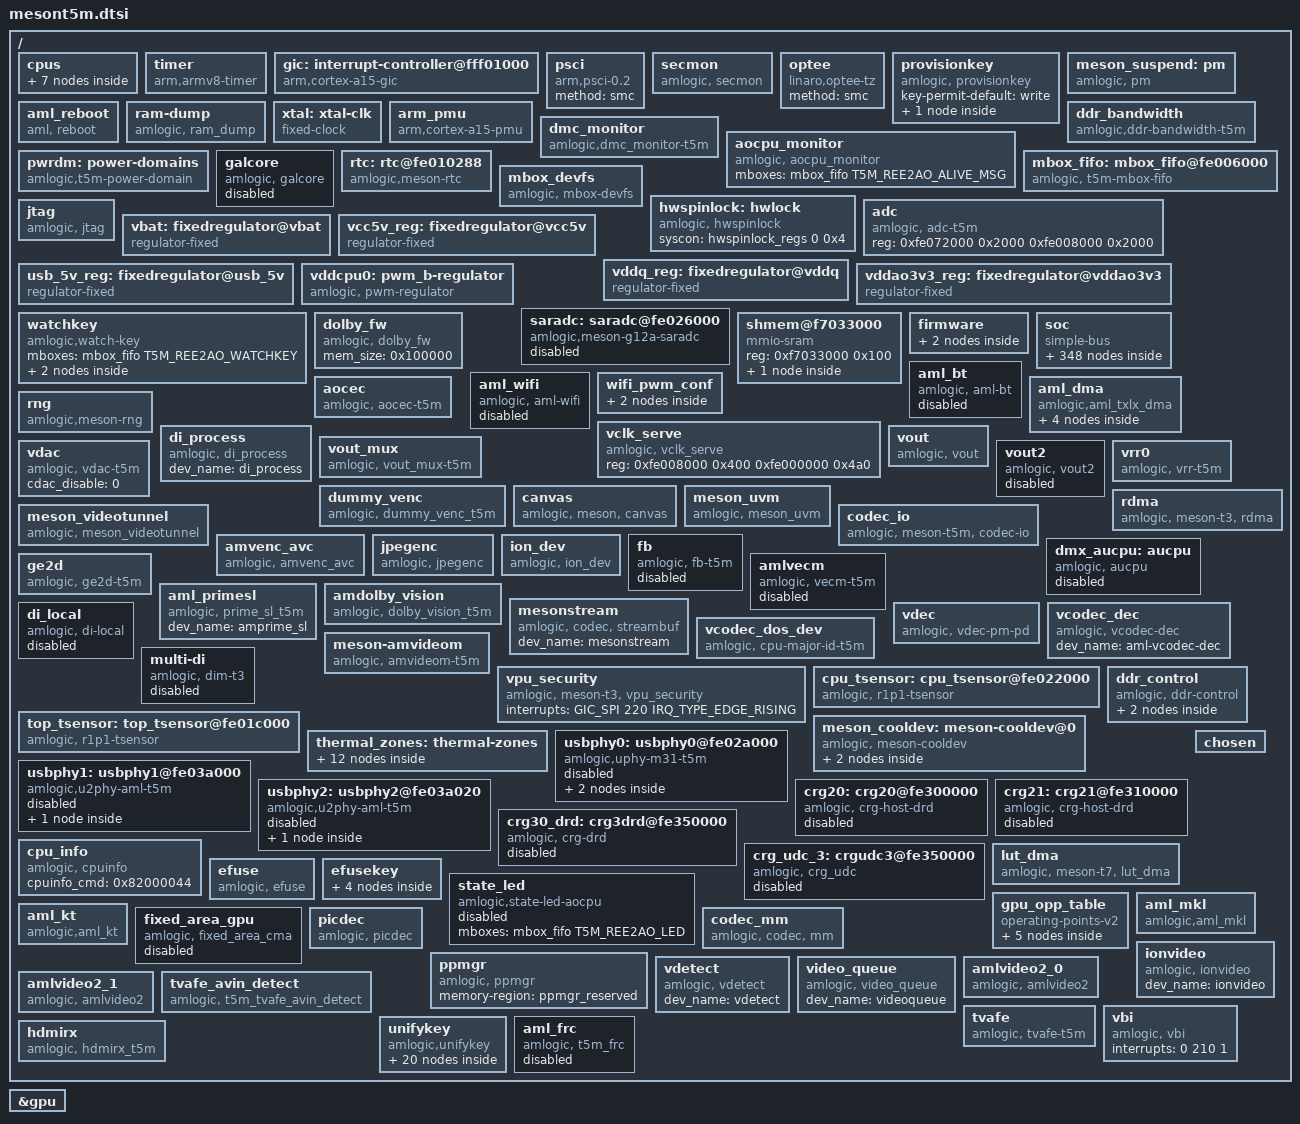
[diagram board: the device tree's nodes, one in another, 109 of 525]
// SPDX-License-Identifier: (GPL-2.0+ OR MIT)
/*
 * Copyright (c) 2019 Amlogic, Inc. All rights reserved.
 */

#include <dt-bindings/interrupt-controller/irq.h>
#include <dt-bindings/interrupt-controller/arm-gic.h>
#include <dt-bindings/reset/amlogic,meson-t5m-reset.h>
#include <dt-bindings/clock/t5m-clkc.h>
#include <dt-bindings/clock/amlogic,t5m-scmi-clk.h>
#include <dt-bindings/clock/amlogic,t3-audio-clk.h>
#include <dt-bindings/gpio/gpio.h>
#include <dt-bindings/gpio/meson-t5m-gpio.h>
#include <dt-bindings/power/t5m-pd.h>
#include <dt-bindings/pwm/pwm.h>
#include <dt-bindings/pwm/meson.h>
#include <dt-bindings/input/input.h>
#include <dt-bindings/input/meson_ir.h>
#include <dt-bindings/iio/adc/amlogic-saradc.h>
#include "meson-ir-map.dtsi"
#include "meson-valhall.dtsi"
#include <dt-bindings/mailbox/t5m-mbox.h>
#include <dt-bindings/thermal/thermal.h>
#include <dt-bindings/thermal/ddr-params.h>
#include <dt-bindings/hwspinlock/amlogic,hwspinlock.h>
#include <dt-bindings/leds/leds-meson.h>

/ {
	cpus:cpus {
		#address-cells = <1>;
		#size-cells = <0>;

		CPU0:cpu@0 {
			device_type = "cpu";
			compatible = "arm,cortex-a55","arm,armv8";
			reg = <0x0>;
			enable-method = "psci";
			cpu-idle-states = <&CPU_SLEEP_0 &SYSTEM_SLEEP_0>;
			#cooling-cells = <2>;
			dynamic-power-coefficient = <230>;
		};

		CPU1:cpu@1{
			device_type = "cpu";
			compatible = "arm,cortex-a55","arm,armv8";
			reg = <0x100>;
			enable-method = "psci";
			cpu-idle-states = <&CPU_SLEEP_0 &SYSTEM_SLEEP_0>;
			#cooling-cells = <2>;
			dynamic-power-coefficient = <230>;
		};

		CPU2:cpu@2 {
			device_type = "cpu";
			compatible = "arm,cortex-a55","arm,armv8";
			reg = <0x200>;
			enable-method = "psci";
			cpu-idle-states = <&CPU_SLEEP_0 &SYSTEM_SLEEP_0>;
			#cooling-cells = <2>;
			dynamic-power-coefficient = <230>;
		};

		CPU3:cpu@3 {
			device_type = "cpu";
			compatible = "arm,cortex-a55","arm,armv8";
			reg = <0x300>;
			enable-method = "psci";
			cpu-idle-states = <&CPU_SLEEP_0 &SYSTEM_SLEEP_0>;
			#cooling-cells = <2>;
			dynamic-power-coefficient = <230>;
		};

		idle-states {
			entry-method = "arm,psci-0.2";
			CPU_SLEEP_0: cpu-sleep-0 {
					compatible = "arm,idle-state";
					arm,psci-suspend-param = <0x0010000>;
					local-timer-stop;
					entry-latency-us = <600>;
					exit-latency-us = <630>;
					min-residency-us = <6140>;
			};
			SYSTEM_SLEEP_0: system-sleep-0 {
					compatible = "arm,idle-state";
					arm,psci-suspend-param = <0x0000000>;
					entry-latency-us = <0x3fffffff>;
					exit-latency-us = <0x40000000>;
					min-residency-us = <0xffffffff>;
			};
		};
	};

	timer {
		compatible = "arm,armv8-timer";
		interrupts = <GIC_PPI 13 0xff08>,
				<GIC_PPI 14 0xff08>,
				<GIC_PPI 11 0xff08>,
				<GIC_PPI 10 0xff08>;
	};

	gic: interrupt-controller@fff01000 {
		compatible = "arm,cortex-a15-gic", "arm,cortex-a9-gic";
		#interrupt-cells = <3>;
		#address-cells = <0>;
		interrupt-controller;
		reg = <0xfff01000 0x1000>,
		      <0xfff02000 0x0100>;
		interrupts = <GIC_PPI 9 0xf04>;
	};

	psci {
		compatible = "arm,psci-0.2";
		method = "smc";
	};

	secmon {
		compatible = "amlogic, secmon";
		memory-region = <&secmon_reserved>;
		in_base_func = <0x82000020>;
		out_base_func = <0x82000021>;
		inout_size_func = <0x8200002a>;
		reserve_mem_size = <0x01C00000>;
	};

	optee {
		compatible = "linaro,optee-tz";
		method = "smc";
	};

	provisionkey {
		compatible = "amlogic, provisionkey";
		status = "okay";
		key-permit-default = "write";
		//new key not need add dts if started with KEY_PROVISION_
		KEY_PROVISION_XXX { };
		//test_my_added_keyname { };
	};//End provisionkey

	meson_suspend:pm {
		compatible = "amlogic, pm";
		status = "okay";
		device_name = "aml_pm";
		extend_resume_reason;
		reg = <0xfe010288 0x4>, /*SYSCTRL_STATUS_REG2*/
			<0xfe0102dc 0x4>; /*SYSCTRL_STICKY_REG7*/
	};

	aml_reboot {
		compatible = "aml, reboot";
		sys_reset = <0x84000009>;
		sys_poweroff = <0x84000008>;
		dis_nb_cpus_in_shutdown;
		extend_reboot_reason; /* Support up to 128 reboot reasons*/
		reg = <0xfe01037c 0x4>; /* SEC_AO_SEC_SD_CFG15 */
		status = "okay";
	};

	ram-dump {
		compatible = "amlogic, ram_dump";
		status = "okay";
		reg = <0xFE0102D8 4>;
		reg-names = "SYSCTRL_STICKY_REG6";
		store_device = "data";
	};

	xtal: xtal-clk {
		compatible = "fixed-clock";
		clock-frequency = <24000000>;
		clock-output-names = "xtal";
		#clock-cells = <0>;
	};

	arm_pmu {
		compatible = "arm,cortex-a15-pmu";
		private-interrupts;
		interrupts = <GIC_SPI 235 IRQ_TYPE_LEVEL_HIGH>,
				<GIC_SPI 236 IRQ_TYPE_LEVEL_HIGH>,
				<GIC_SPI 237 IRQ_TYPE_LEVEL_HIGH>,
				<GIC_SPI 238 IRQ_TYPE_LEVEL_HIGH>;

		reg = <0xff634680 0x4>;
	};

	ddr_bandwidth {
		compatible = "amlogic,ddr-bandwidth-t5m";
		status = "okay";
		reg = <0xfe036000 0x400
		       0xfe034000 0x400
		       0xfe0368a4 0x4>;
		freq_reg = <0xfe0348a4>;
		interrupts = <0 136 IRQ_TYPE_EDGE_RISING
			      0 140 IRQ_TYPE_EDGE_RISING>;
		interrupt-names = "ddr_bandwidth";
	};

	dmc_monitor {
		compatible = "amlogic,dmc_monitor-t5m";
		status = "okay";
		memory-region = <&dmc_reserved>;
		reg = <0xfe036000 0x400
		       0xfe034000 0x400>;
		reg_base = <0xfe036000>;
		interrupts = <0 137 IRQ_TYPE_LEVEL_HIGH
			      0 141 IRQ_TYPE_LEVEL_HIGH
			      0 139 IRQ_TYPE_EDGE_RISING
			      0 143 IRQ_TYPE_EDGE_RISING>;
	};

	aocpu_monitor {
		compatible = "amlogic, aocpu_monitor";
		status = "okay";
		mboxes = <&mbox_fifo T5M_REE2AO_ALIVE_MSG>;
	};

	pwrdm: power-domains {
		compatible = "amlogic,t5m-power-domain";
		#power-domain-cells = <1>;
		status = "okay";
	};

	galcore {
		compatible = "amlogic, galcore";
		dev_name = "galcore";
		status = "disabled";
		//clocks = <&clkc CLKID_CTS_NNA_AXI_CLK>,
		//      <&clkc CLKID_CTS_NNA_CORE_CLK>,
		//      <&clkc CLKID_SYS1_PLL>;
		//clock-names = "cts_vipnanoq_axi_clk_composite",
		//      "cts_vipnanoq_core_clk_composite",
		//      "sys1_pll";
		assigned-clocks =  <&scmi_clk CLKID_SYS1_PLL>;
		assigned-clock-rates =  <1704000000>;
		interrupts = <0 59 4>;
		interrupt-names = "galcore";
		//power-domains = <&pwrdm PDID_T3_NNA>;
		reg = <0xfdb00000 0x40000
		      0xfe090000 0x2000
		      0xfe00c0a4 0x4
		      0xfe00c0a8 0x4
		      0xfe00c034 0x4
		      0xfe000220 0x4>;
		reg-names = "NN_REG","NN_SRAM","NN_MEM0",
		      "NN_MEM1","NN_RESET","NN_CLK";
		nn_power_version = <5>;
	};

	rtc: rtc@fe010288 {
		compatible = "amlogic,meson-rtc";
		reg = <0xfe010288 0x4>; //SYSCTRL_STATUS_REG2
		interrupts = <GIC_SPI 3 IRQ_TYPE_EDGE_RISING>;
		status = "okay";
		mboxes = <&mbox_fifo T5M_REE2AO_VRTC>;
		rtc-virtual;
	};

	aml_reboot {
		compatible = "aml, reboot";
		sys_reset = <0x84000009>;
		sys_poweroff = <0x84000008>;
		dis_nb_cpus_in_shutdown;
	};

	mbox_fifo: mbox_fifo@fe006000 {
		status = "okay";
		compatible = "amlogic, t5m-mbox-fifo";
		reg = <0xfe006000 0x800>,  /* mbox wr fifo */
		      <0xfe007180 0x80>,   /* mbox set reg */
		      <0xfe007200 0x80>,   /* mbox clr reg */
		      <0xfe007280 0x80>,   /* mbox sts reg */
		      <0xfe007040 0xc0>;   /* mbox irqctrl reg */
		interrupts = <GIC_SPI 248 IRQ_TYPE_EDGE_RISING>;  /* mbox irq top */
		mbox-irqmax = <32>;
		mbox-irqctlr = <0x14>;
		mbox-irqclr = <0x8>;
		mbox-nums = <T5M_MBOX_NUMS>;
		mboxids = <T5M_MBOX_AO2REE>,
			  <T5M_MBOX_REE2AO>;
		#mbox-cells = <1>;
		mbox-wr-same;
		mbox-dests = <MAILBOX_ARM>,
			     <MAILBOX_AOCPU>;
		aocpu-hang-detect;
		aocpu-sts-mboxid = <T5M_AOCPU_STS_CHAN>;
	};

	mbox_devfs {
		status = "okay";
		compatible = "amlogic, mbox-devfs";
		mbox-nums = <2>;
		mbox-names = "ree2aocpu",
			     "aocpu2ree";
		mboxes = <&mbox_fifo T5M_REE2AO_DEV>,
			 <&mbox_fifo T5M_AO2REE_DEV>;
	};

	hwspinlock: hwlock {
		status = "okay";
		compatible = "amlogic, hwspinlock";
		syscon = <&hwspinlock_regs 0 0x4>;
		#hwlock-cells = <1>;
	};

	adc: adc {
		compatible = "amlogic, adc-t3";
		status = "disabled";
		reg = <0xfe072000 0x2000/* afe reg base */
			0xfe008000 0x2000/* ana base */
			>;
	};

	jtag {
		compatible = "amlogic, jtag";
		status = "okay";
		select = "disable"; /* disable/jtag_a/jtag_b */
		pinctrl-names="jtag_a_pins";
		pinctrl-0=<&jtag_a_pins>;
	};

	vbat: fixedregulator@vbat {
		compatible = "regulator-fixed";
		regulator-name = "12V";
		regulator-min-microvolt = <12000000>;
		regulator-max-microvolt = <12000000>;
		regulator-boot-on;
		regulator-always-on;
	};

	vcc5v_reg: fixedregulator@vcc5v {
		vin-supply = <&vbat>;
		compatible = "regulator-fixed";
		regulator-name = "5V/VCC_5V";
		regulator-min-microvolt = <5000000>;
		regulator-max-microvolt = <5000000>;
		gpio = <&gpio GPIO_TEST_N GPIO_ACTIVE_HIGH>;
		startup-delay-us = <7000>;
		enable-active-high;
		regulator-boot-on;
		regulator-always-on;
	};

	usb_5v_reg: fixedregulator@usb_5v{
		compatible = "regulator-fixed";
		vin-supply = <&vcc5v_reg>;
		regulator-name = "USB_5V";
		regulator-min-microvolt = <5000000>;
		regulator-max-microvolt = <5000000>;
		regulator-boot-on;
		regulator-always-on;
	};

	vddq_reg: fixedregulator@vddq {
		compatible = "regulator-fixed";
		vin-supply = <&vbat>;
		regulator-name = "VDDQ";
		regulator-min-microvolt = <1220000>;
		regulator-max-microvolt = <1220000>;
		pinctrl-names = "default";
		gpio = <&gpio GPIOD_4 GPIO_ACTIVE_HIGH>;
		startup-delay-us = <7000>;
		enable-active-high;
		regulator-boot-on;
		regulator-always-on;
	};

	vddao3v3_reg: fixedregulator@vddao3v3 {
		vin-supply = <&vbat>;
		compatible = "regulator-fixed";
		regulator-name = "VDDAO_3.3V";
		regulator-min-microvolt = <3300000>;
		regulator-max-microvolt = <3300000>;
		regulator-boot-on;
		regulator-always-on;
	};

	vddcpu0: pwm_b-regulator {
		compatible = "amlogic, pwm-regulator";
		pwms = <&pwm_ab MESON_PWM_1 1512 0>;
		regulator-name = "vddcpu0";
		regulator-min-microvolt = <689000>;
		regulator-max-microvolt = <1049000>;
		regulator-always-on;
		max-duty-cycle = <1512>;
		amlogic,vsel-step = <3>;
		amlogic,usleep-time = <200>;
		/* Voltage Duty-Cycle */
		voltage-table = <1049000 0>,
				<1039000 3>,
				<1029000 6>,
				<1019000 8>,
				<1009000 11>,
				<999000 14>,
				<989000 17>,
				<979000 19>,
				<969000 22>,
				<959000 25>,
				<949000 28>,
				<939000 31>,
				<929000 33>,
				<919000 36>,
				<909000 39>,
				<899000 42>,
				<889000 44>,
				<879000 47>,
				<869000 50>,
				<859000 53>,
				<849000 56>,
				<839000 58>,
				<829000 61>,
				<819000 64>,
				<809000 67>,
				<799000 69>,
				<789000 72>,
				<779000 75>,
				<769000 78>,
				<759000 81>,
				<749000 83>,
				<739000 86>,
				<729000 89>,
				<719000 92>,
				<709000 94>,
				<699000 97>,
				<689000 100>;
		status = "okay";
	};

	saradc: saradc@fe026000 {
		compatible = "amlogic,meson-g12a-saradc",
			   "amlogic,meson-saradc";
		status = "disabled";
		#io-channel-cells = <1>;
		clocks = <&xtal>,
		    <&clkc CLKID_SYS_CLK_SAR_ADC>,
		    <&clkc CLKID_SARADC>,
		    <&clkc CLKID_SARADC_SEL>;
		clock-names = "clkin", "core",
		    "adc_clk", "adc_sel";
		interrupts = <GIC_SPI 181 IRQ_TYPE_EDGE_RISING>;
		reg = <0xfe026000 0x48>;
		watch-key = <&wk_adckey>;
	};

	watchkey: watchkey {
		compatible = "amlogic,watch-key";
		mboxes = <&mbox_fifo T5M_REE2AO_WATCHKEY>;

		wk_adckey: wk-0 {
			wk-name = "adc-keypad";
			wk-id = <0>;
			wk-type = <EV_KEY>;
			wk-code = <KEY_POWER>;
			/* wk-report-event; */
		};

		wk_gpiokey: wk-1 {
			wk-name = "gpio-keypad";
			wk-id = <1>;
			wk-type = <EV_KEY>;
			wk-code = <KEY_POWER>;
			/* wk-report-event; */
		};
	};

	dolby_fw: dolby_fw {
		compatible = "amlogic, dolby_fw";
		mem_size = <0x100000>;
		status = "okay";
	};

	shmem@f7033000 {
		compatible = "mmio-sram";
		reg = <0xf7033000 0x100>;
		#address-cells = <1>;
		#size-cells = <1>;
		ranges = <0x0 0xf7033000 0x100>;

		scmi_shmem: shmem@0 {
			compatible = "arm,scmi-shmem";
			reg = <0x0 0x100>;
		};
	};

	firmware {
		scmi: scmi {
			compatible = "arm,scmi-smc";
			arm,smc-id = <0x820000c1>;
			shmem = <&scmi_shmem>;
			#address-cells = <1>;
			#size-cells = <0>;

			scmi_clk: protocol@14 {
				reg = <0x14>;
				#clock-cells = <1>;
			};
		};
	};

	soc {
		compatible = "simple-bus";
		#address-cells = <1>;
		#size-cells = <1>;
		ranges;

		apb4: apb4@fe000000 {
			compatible = "simple-bus";
			reg = <0xfe000000 0x480000>;
			#address-cells = <1>;
			#size-cells = <1>;
			ranges = <0x0 0xfe000000 0x480000>;

			reset: reset-controller@2000 {
				compatible = "amlogic,meson-t5m-reset";
				reg = <0x2000 0x98>;
				#reset-cells = <1>;
			};

			watchdog@2100 {
				compatible = "amlogic,meson-sc2-wdt";
				status = "okay";
				/* 0:userspace, 1:kernel */
				amlogic,feed_watchdog_mode = <1>;
				reg = <0x2100 0x10>;
				clocks = <&xtal>;
			};

			clkc: clock-controller {
				compatible = "amlogic,t5m-clkc";
				#clock-cells = <1>;
				reg = <0x0 0x230>,
				      <0x8000 0x3e4>,
				      <0xe140 0x20>;
				reg-names = "basic", "pll",
					    "cpu_clk";
				clocks = <&xtal>;
				clock-names = "xtal";
				status = "okay";
			};

			meson_clk_msr@48000 {
				compatible = "amlogic,meson-t5m-clk-measure";
				reg = <0x48000 0x1c>;
				status = "okay";
			};

			uart_B: serial@7a000 {
				compatible = "amlogic,meson-uart";
				reg = <0x7a000 0x18>;
				interrupts = <0 169 1>;
				status = "disabled";
				clocks = <&xtal>;
				clock-names = "clk_uart";
				xtal_tick_en = <2>;
				fifosize = < 64 >;
				/* 0 not support; 1 support */
				support-sysrq = <1>;
			};

			periphs_pinctrl: pinctrl@4000 {
				compatible = "amlogic,meson-t5m-periphs-pinctrl";
				#address-cells = <1>;
				#size-cells = <1>;
				ranges;

				gpio: bank@4000 {
					reg = <0x4000 0x0058>,
					      <0x40c0 0x030c>;
					reg-names = "mux", "gpio";
					gpio-controller;
					#gpio-cells = <2>;
					gpio-ranges = <&periphs_pinctrl 0 0 150>;
				};
			};

			analog_pinctrl: analog-pinctrl@4054 {
				compatible = "amlogic,meson-t5m-analog-pinctrl";
				#address-cells = <1>;
				#size-cells = <1>;
				ranges;

				analog_gpio: analog-bank@4054 {
					reg = <0x405c 0x0008>,
					      <0x43cc 0x0008>;
					reg-names = "mux", "gpio";
					gpio-controller;
					#gpio-cells = <2>;
					gpio-ranges = <&analog_pinctrl 0 0 8>;
				};
			};

			gpio_intc: interrupt-controller@4080 {
				compatible = "amlogic,meson-t5m-gpio-intc",
					     "amlogic,meson-gpio-intc";
				reg = <0x4080 0x20>;
				interrupt-controller;
				#interrupt-cells = <2>;
				amlogic,channel-interrupts =
					<10 11 12 13 14 15 16 17 18 19 20 21>;
			};

			spicc0: spi@50000 {
				compatible = "amlogic,meson-s5-spicc";
				reg = <0x50000 0x58>;
				interrupts = <GIC_SPI 183 IRQ_TYPE_LEVEL_HIGH>;
				clocks = <&clkc CLKID_SYS_CLK_SPICC0>,
					 <&clkc CLKID_SPICC0>;
				clock-names = "core", "async";
				#address-cells = <1>;
				#size-cells = <0>;
				//power-domains = <&pwrdm PDID_T3_SPICC0>;
				reset-names = "spicc";
				resets = <&reset RESET_SPICC_0>;
				status = "disabled";
			};

			spicc1: spi@52000 {
				compatible = "amlogic,meson-s5-spicc";
				reg = <0x52000 0x58>;
				interrupts = <GIC_SPI 184 IRQ_TYPE_LEVEL_HIGH>;
				clocks = <&clkc CLKID_SYS_CLK_SPICC1>,
					 <&clkc CLKID_SPICC1>;
				clock-names = "core", "async";
				#address-cells = <1>;
				#size-cells = <0>;
				//power-domains = <&pwrdm PDID_T3_SPICC1>;
				reset-names = "spicc";
				resets = <&reset RESET_SPICC_1>;
				status = "disabled";
			};

			spicc2: spi@54000 {
				compatible = "amlogic,meson-s5-spicc";
				reg = <0x54000 0x58>;
				interrupts = <GIC_SPI 167 IRQ_TYPE_LEVEL_HIGH>;
				clocks = <&clkc CLKID_SYS_CLK_SPICC2>,
					 <&clkc CLKID_SPICC2>;
				clock-names = "core", "async";
				#address-cells = <1>;
				#size-cells = <0>;
				//power-domains = <&pwrdm PDID_T3_SPICC2>;
				reset-names = "spicc";
				resets = <&reset RESET_SPICC_2>;
				status = "disabled";
			};

			spifc: spi@56000 {
				compatible = "amlogic,meson-spifc";
				status = "disabled";
				reg = <0x56000 0x80>;
				clock-names = "default";
				clocks = <&clkc CLKID_SYS_CLK_SPIFC>;
				pinctrl-names = "default";
				pinctrl-0 = <&spifc_all_pins>;
				#address-cells = <1>;
				#size-cells = <0>;
				spi-nor@0 {
					compatible = "jedec,spi-nor";
					status = "disabled";
					reg = <0>;
					spi-max-frequency = <16000000>;
				};
			};

			pwm_ab: pwm@58000 {
				compatible = "amlogic,meson-v2-pwm";
				reg = <0x58000 0x24>,
					  <0x180 0x4>;
				#pwm-cells = <3>;
				clocks = <&clkc CLKID_PWM_A_SEL>,
					     <&clkc CLKID_PWM_B_SEL>;
				clock-names = "clkin0", "clkin1";
				status = "okay";
			};

			pwm_cd: pwm@5a000 {
				compatible = "amlogic,meson-v2-pwm";
				reg = <0x5a000 0x24>,
					  <0x184 0x4>;
				#pwm-cells = <3>;
				clocks = <&clkc CLKID_PWM_C_SEL>,
					     <&clkc CLKID_PWM_D_SEL>;
				clock-names = "clkin0", "clkin1";
				status = "disabled";
			};

			pwm_ef: pwm@5c000 {
				compatible = "amlogic,meson-v2-pwm";
				reg = <0x5c000 0x24>,
					  <0x188 0x4>;
				#pwm-cells = <3>;
				clocks = <&clkc CLKID_PWM_E_SEL>,
					     <&clkc CLKID_PWM_F_SEL>;
				clock-names = "clkin0", "clkin1";
				status = "disabled";
			};

			pwm_gh: pwm@5e000 {
				compatible = "amlogic,meson-v2-pwm";
				reg = <0x5e000 0x24>,
					  <0x18c 0x4>;
				#pwm-cells = <3>;
				clocks = <&clkc CLKID_PWM_G_SEL>,
					     <&clkc CLKID_PWM_H_SEL>;
				clock-names = "clkin0", "clkin1";
				status = "disabled";
			};

			i2c0: i2c@66000 {
				compatible = "amlogic,meson-i2c";
				reg = <0x66000 0x48>;
				interrupts = <GIC_SPI 160 IRQ_TYPE_EDGE_RISING>;
				#address-cells = <1>;
				#size-cells = <0>;
				clocks = <&clkc CLKID_SYS_CLK_I2C_M_A>;
				status = "disabled";
			};

			i2c1: i2c@68000 {
				compatible = "amlogic,meson-i2c";
				reg = <0x68000 0x48>;
				interrupts = <GIC_SPI 161 IRQ_TYPE_EDGE_RISING>;
				#address-cells = <1>;
				#size-cells = <0>;
				clocks = <&clkc CLKID_SYS_CLK_I2C_M_B>;
				status = "disabled";
			};

			i2c2: i2c@6a000 {
				compatible = "amlogic,meson-i2c";
				reg = <0x6a000 0x48>;
				interrupts = <GIC_SPI 162 IRQ_TYPE_EDGE_RISING>;
				#address-cells = <1>;
				#size-cells = <0>;
				clocks = <&clkc CLKID_SYS_CLK_I2C_M_C>;
				status = "okay";
			};

			i2c3: i2c@6c000 {
				compatible = "amlogic,meson-i2c";
				reg = <0x6c000 0x48>;
				interrupts = <GIC_SPI 163 IRQ_TYPE_EDGE_RISING>;
				#address-cells = <1>;
				#size-cells = <0>;
				clocks = <&clkc CLKID_SYS_CLK_I2C_M_D>;
				status = "disabled";
			};

			i2c4: i2c@6e000 {
				compatible = "amlogic,meson-i2c";
				reg = <0x6e000 0x48>;
				interrupts = <GIC_SPI 164 IRQ_TYPE_EDGE_RISING>;
				#address-cells = <1>;
				#size-cells = <0>;
				clocks = <&clkc CLKID_SYS_CLK_I2C_M_E>;
				status = "disabled";
			};

			dcon_led: dcon_led@74000 {
				compatible = "amlogic,led_unipolar_ctrl";
				reg = <0x74000 0x88>;
				interrupts = <GIC_SPI 30 IRQ_TYPE_EDGE_RISING>;
				led-mode = <LED_MESON_GRB>;
				led_number = <2>;
				status = "disabled";
			};

			ir: ir@8000 {
				compatible = "amlogic, meson-ir";
				reg = <0x84040 0xA4>,
					<0x84000 0x20>;
				status = "disabled";
				protocol = <REMOTE_TYPE_NEC>;
				interrupts = <GIC_SPI 22 IRQ_TYPE_EDGE_RISING>;
				map = <&custom_maps>;
				wakeup_map = <&ir_wakeup_key>;
				mboxes = <&mbox_fifo T5M_REE2AO_IR>;
				max_frame_time = <200>;
			};

			irblaster: meson-irblaster@fe08410c {
				compatible = "amlogic, meson_irblaster";
				status = "disabled";
				reg = <0x8410c 0x10>;
				#irblaster-cells = <2>;
				interrupts = <GIC_SPI 23 IRQ_TYPE_EDGE_RISING>;
			};

			eth_phy: mdio-multiplexer@28000 {
				compatible = "amlogic,g12a-mdio-mux";
				reg = <0x28000 0xa4>;

				clocks = <&clkc CLKID_SYS_CLK_ETHPHY>,
					 <&xtal>,
					 <&clkc CLKID_MPLL_50M>;
				clock-names = "pclk", "clkin0", "clkin1";
				mdio-parent-bus = <&mdio0>;
				#address-cells = <1>;
				#size-cells = <0>;
				enet_type = <5>;
				tx_amp_src = <0xFE010330>;

				ext_mdio: mdio@0 {
					reg = <0>;
					#address-cells = <1>;
					#size-cells = <0>;
				};

				int_mdio: mdio@1 {
					reg = <1>;
					#address-cells = <1>;
					#size-cells = <0>;

					internal_ephy: ethernet_phy@8 {
						compatible = "ethernet-phy-id0180.3301",
							     "ethernet-phy-ieee802.3-c22";
						interrupts = <GIC_SPI 219 IRQ_TYPE_LEVEL_HIGH>;
						reg = <8>;
						max-speed = <100>;
					};
				};
			};

			hwspinlock_regs: syscon@e2c0 {
				compatible = "syscon";
				reg = <0xe2c0 0x20>;
			};
		};

		ethmac: ethernet@fdc00000 {
			compatible = "amlogic,meson-axg-dwmac",
				     "snps,dwmac-3.70a",
				     "snps,dwmac";
			reg = <0xfdc00000 0x10000>,
			      <0xfe024000 0x8>;
			interrupts = <GIC_SPI 74 IRQ_TYPE_LEVEL_HIGH>;
			interrupt-names = "macirq";
			//power-domains = <&pwrdm PDID_T3_ETH>;
			clocks = <&clkc CLKID_SYS_CLK_ETH>,
				 <&clkc CLKID_FCLK_DIV2>,
				 <&clkc CLKID_MPLL_50M>;
			clock-names = "stmmaceth", "clkin0", "clkin1";
			rx-fifo-depth = <4096>;
			tx-fifo-depth = <2048>;
			/*1:inphy; 2:exphy;*/
			internal_phy = <1>;
			mboxes = <&mbox_fifo T5M_REE2AO_ETH>;
			status = "disabled";

			mdio0: mdio {
				#address-cells = <1>;
				#size-cells = <0>;
				compatible = "snps,dwmac-mdio";
			};
		};

		uart_A: serial@fe078000 {
			compatible = "amlogic,meson-uart";
			reg = <0xfe078000 0x18>;
			interrupts = <0 168 1>;
			status = "disabled";
			clocks = <&xtal
				&clkc CLKID_SYS_CLK_UART_A>;
			clock-names = "clk_uart",
				"clk_gate";
			xtal_tick_en = <2>;
			fifosize = < 64 >;
			pinctrl-names = "default";
			pinctrl-0 = <&a_uart_pins1>;
		};

		uart_C: serial@fe07c000 {
			compatible = "amlogic,meson-uart";
			reg = <0xfe07c000 0x18>;
			interrupts = <0 170 1>;
			status = "disabled";
			clocks = <&xtal
				&clkc CLKID_SYS_CLK_UART_C>;
			clock-names = "clk_uart",
				"clk_gate";
			xtal_tick_en = <2>;
			fifosize = < 64 >;
			pinctrl-names = "default";
			pinctrl-0 = <&c_uart_pins1>;
		};

		sd_emmc_c: mmc@fe08c000 {
			compatible = "amlogic,meson-axg-mmc";
			reg = <0xfe08c000 0x800>,
				<0xfe000168 0x4>,
				<0xfe004000 0x4>;
			interrupts = <GIC_SPI 178 IRQ_TYPE_EDGE_RISING>;
			status = "disabled";
			clocks = <&clkc CLKID_SYS_CLK_SD_EMMC_C>,
				<&clkc CLKID_SD_EMMC_C_SEL>,
				<&clkc CLKID_SD_EMMC_C>,
				<&xtal>,
				<&clkc CLKID_GP0_PLL>,
				<&clkc CLKID_GP0_PLL>;
			clock-names = "core", "mux0", "mux1",
					"clkin0", "clkin1", "clkin2";

			card_type = <1>;
			src_clk_rate = <1544400000>;
			mmc_debug_flag;
			ignore_desc_busy;
			tx_delay = <18>;
			save_para = <1>;
			no-sd;
			no-sdio;
			resets = <&reset RESET_SD_EMMC_C>;
		};

		sd_emmc_b: sd@fe08a000 {
			compatible = "amlogic,meson-axg-mmc";
			reg = <0xfe08a000 0x800>,
				<0xfe00016c 0x4>,
				<0xfe004008 0x4>;
			interrupts = <GIC_SPI 177 IRQ_TYPE_EDGE_RISING>;
			status = "disabled";
			clocks = <&clkc CLKID_SYS_CLK_SD_EMMC_B>,
				<&clkc CLKID_SD_EMMC_B_SEL>,
				<&clkc CLKID_SD_EMMC_B>,
				<&xtal>,
				<&clkc CLKID_FCLK_DIV2>;
			clock-names = "core", "mux0", "mux1",
					"clkin0", "clkin1";
			card_type = <5>;
			//use_intf3_tuning;
			mmc_debug_flag;
			no-mmc;
			no-sdio;
			//resets = <&reset RESET_SD_EMMC_B>;
		};

		dummy_codec:dummy{
			#sound-dai-cells = <0>;
			compatible = "amlogic, aml_dummy_codec";
			status = "okay";
		};

		v2d {
			compatible = "amlogic, v2d";
			dev_name = "v2d";
			status = "okay";
		};

		videodisplay {
			compatible = "amlogic, videodisplay";
			dev_name = "videodisplay";
			status = "okay";
		};

		video_composer {
			compatible = "amlogic, video_composer";
			dev_name = "video_composer";
			status = "okay";
		};

		acodec:codec {
			#sound-dai-cells = <0>;
			compatible = "amlogic, t5w_acodec";
			status = "okay";
			reg = <0xfe01a000 0x24>, <0xFE330740 0x4>;
			reg-names = "acodec", "to_acodec";
			tdmout_index = <1>;
			tdmin_index = <1>;
			dat0_ch_sel = <2>;
			lane_offset = <4>;
			reset-names = "acodec";
			resets = <&reset RESET_ACODEC>;
		};

		audio_data: audio_data {
			compatible = "amlogic, audio_data";
			mem_in_base_cmd = <0x82000020>;
			query_licence_cmd = <0x82000050>;
			status = "okay";
		};

		amaudio: amaudio {
			compatible = "amlogic, amaudio";
			reg = <0xfe440000 0x10000>;
			reg-names = "otp_tee_base";
			status = "okay";
		};

		audiobus: audiobus@FE330000 {
			compatible = "amlogic, audio-controller", "simple-bus";
			#address-cells = <1>;
			#size-cells = <1>;
			reg = <0xFE330000 0x3000>;
			ranges = <0x0 0xFE330000 0x3000>;
			chip_id = <0x41>;
			clkaudio:audio_clocks {
				compatible = "amlogic, t5m-audio-clocks";
				#clock-cells = <1>;
				reg = <0x0 0xb0>;
			};
			ddr_manager {
				compatible =
					"amlogic, t5-audio-ddr-manager";
				interrupts = <
					GIC_SPI 32 IRQ_TYPE_EDGE_RISING
					GIC_SPI 33 IRQ_TYPE_EDGE_RISING
					GIC_SPI 34 IRQ_TYPE_EDGE_RISING
					GIC_SPI 45 IRQ_TYPE_EDGE_RISING
					GIC_SPI 36 IRQ_TYPE_EDGE_RISING
					GIC_SPI 37 IRQ_TYPE_EDGE_RISING
					GIC_SPI 38 IRQ_TYPE_EDGE_RISING
					GIC_SPI 46 IRQ_TYPE_EDGE_RISING
				>;
				interrupt-names =
					"toddr_a", "toddr_b", "toddr_c",
					"toddr_d",
					"frddr_a", "frddr_b", "frddr_c",
					"frddr_d";
			};
			pcpd_monitor_a: pcpd_monitor@0 {
				compatible = "amlogic, pcpda_monitor";
				/*regbase:0xFE330000 + 0x3b0 << 2*/
				/*size 0x28 byte*/
				reg =<0xec0 0x28>;
				reg-names = "pcpd_reg";
				interrupts = <GIC_SPI 149
					IRQ_TYPE_EDGE_RISING>;
				interrupt-names = "irq_pcpd";
				status = "okay";
			};
			pcpd_monitor_b: pcpd_monitor@1 {
				compatible = "amlogic, pcpdb_monitor";
				reg =<0xf00 0x28>;
				reg-names = "pcpd_reg";
				interrupts = <GIC_SPI 148
					IRQ_TYPE_EDGE_RISING>;
				interrupt-names = "irq_pcpd";
				status = "okay";
			};

			pinctrl_audio: pinctrl {
				compatible = "amlogic, audio-pinctrl";
			};

			extn:extn {
				compatible = "amlogic, t5m-snd-extn";
				#sound-dai-cells = <0>;
				interrupts = <GIC_SPI 42 IRQ_TYPE_EDGE_RISING>;
				interrupt-names = "irq_frhdmirx";
				status = "okay";
			};
		};/* end of audiobus*/

		vpu: vpu {
			compatible = "amlogic, vpu-t5m";
			status = "okay";
			reg =   <0xfe000000 0x100    /* clk */
				0xfe00c000 0x70     /* pwrctrl */
				0xff800000 0xf000>; /* vcbus */
			clocks = <&clkc CLKID_VAPB_0>,
				<&clkc CLKID_VAPB_1>,
				<&clkc CLKID_VAPB>,
				<&clkc CLKID_VPU_0>,
				<&clkc CLKID_VPU_1>,
				<&clkc CLKID_VPU>,
				<&clkc CLKID_GP0_PLL>;
			clock-names =   "vapb_clk0",
					"vapb_clk1",
					"vapb_clk",
					"vpu_clk0",
					"vpu_clk1",
					"vpu_clk",
					"gp_pll";
			clk_level = <8>;
			/* 0: 24.0M  1: 100.0M    2: 166.7M    3: 200.0M    4: 250.0M */
			/* 5: 333.3M    6: 400.0M    7: 500.0M    8: 666.7M */
			/* 9: 800M      10: 744M      11:768M */
		};

		/*if you want to use vdin just modify status to "ok"*/
		vdin0: vdin0 {/*common define*/
			status = "okay";
			compatible = "amlogic, vdin-t5m";
			dev_name = "vdin0";
			/*status = "disabled";*/
			/*memory-region = <&vdin0_cma_reserved>;*/
			reserve-iomap = "true";
			flag_cma = <0x10101>;/*1:share with codec_mm;2:cma alone*/
			/*MByte, if 10bit disable: 64M(YUV422),
			 *if 10bit enable: 64*1.5 = 96M(YUV422)
			 *if support 4K2K-YUV444-10bit-WR:3840*2160*4*4 ~= 128M
			 *if support 4K2K-YUV422-10bit-wr:3840*2160*3*4 ~= 96M
			 *if support 4K2K-YUV422-8BIT-WR:3840*2160*2*4 ~= 64M
			 *if support 1080p-YUV422-8BIT-WR:1920*1080*2*4 ~= 16M
			 * onebuffer:
			 * worst case:(4096*2160*3 + 2M(afbce issue)) = 27.5M
			 * dw:960x540x3 = 1.5M
			 * total size:(27.5+1.5)x buffernumber
			 */
			/*cma_size = <174>;*/
			/*frame_buff_num = <6>;*/
			interrupts = <0 210 1 /* vdin0 vsync */
					/*0 214 1*/ /* vdin1 write down*/
					/*0 206 1*/ /* vpu crash */
					/*0 213 1*/>; /* vdin0 write down*/
			interrupt-names = "vsync_int"
					/*"mif2_meta_wr_done_int"*/
					/*"vpu_crash_int",*/
					/*"write_done_int"*/;
			rdma-irq = <2>;
			clocks = <&clkc CLKID_FCLK_DIV5>, <&clkc CLKID_VDIN_MEAS>;
				clock-names = "fclk_div5", "cts_vdin_meas_clk";
			vdin_id = <0>;
			/*vdin write mem color depth support:
			 * bit0:support 8bit
			 * bit1:support 9bit
			 * bit2:support 10bit
			 * bit3:support 12bit
			 * bit4:support yuv422 10bit full pack mode (from txl new add)
			 * bit5:force yuv422 to yuv444 malloc (for vdin0 debug)
			 * bit8:use 8bit  at 4k_50/60hz_10bit
			 * bit9:use 10bit at 4k_50/60hz_10bit
			 * bit10: support 10bit when double write
			 */
			tv_bit_mode = <0x235>;
			/* afbce_bit_mode: (amlogic frame buff compression encoder)
			 * bit0 -- enable afbce
			 * bit1 -- enable afbce compression-lossy
			 * bit4 -- afbce for 4k
			 * bit5 -- afbce for 1080p
			 * bit6 -- afbce for 720p
			 * bit7 -- afbce for smaller resolution
			 */
			afbce_bit_mode = <0x13>;
			chk_wr_done_en;
			/* urgent_en; */
			double_write_en;
			vdin_function_sel = <0x20000>;
			/* vdin v4l2 */
			v4l_support_en = <0>;
			v4l_vd_num = <70>;
			/* v4l2 capability */
			driver   = "vdinvideo";
			card     = "mesont3";
			bus_info = "vdin0 v4l2";
			version  = <0x20220120>;
			/* fe_ports refer to tvin.h */
			fe_ports = <0x00001001   /* CVBS1 */
				0x00004000   /* HDMI0 */
				0x00004001   /* HDMI1 */
				0x00004002>; /* HDMI2 */
			/* vdin v4l2 end */
		};

		vdin1: vdin1 {/*common define*/
			status = "okay";
			compatible = "amlogic, vdin-t5m";
			dev_name = "vdin1";
			/*status = "disabled";*/
			reserve-iomap = "true";
			/*memory-region = <&vdin1_cma_reserved>;*/
			flag_cma = <0>;/*1:share with codec_mm;0:cma alone*/
			interrupts = <0 212 1>;
			interrupt-names = "vsync_int"/*, "vpu_crash_int",*/
					/*"write_done_int"*/;
			rdma-irq = <4>;
			clocks = <&clkc CLKID_FCLK_DIV5>, <&clkc CLKID_VDIN_MEAS>;
				clock-names = "fclk_div5", "cts_vdin_meas_clk";
			vdin_id = <1>;
			tv_bit_mode = <0x15>;
			/* vdin v4l2 */
			v4l_support_en = <0>;
			v4l_vd_num = <71>;
			/* v4l2 capability */
			driver   = "vdinvideo";
			card     = "mesont3";
			bus_info = "vdin1 v4l2";
			version  = <0x20220120>;
			/* fe_ports refer to tvin.h */
			fe_ports = <0x0000a002   /* WB0_VD1 */
				0x0000a003   /* WB0_VD2 */
				0x0000a004   /* WB0_OSD1 */
				0x0000a005   /* WB0_OSD2 */
				0x0000a006   /* WB0_VPP */
				0x0000a007   /* WB0_VDIN_BIST */
				0x0000a008   /* WB0_POST_BLEND */
				0x0000a001>; /* VIDEO */
			/* vdin v4l2 end */
		};

		amvdec_656in {
			/*bt656 gpio conflict with i2c0*/
			compatible = "amlogic, bt656in-t3";
			dev_name = "amvdec_656in";
			status = "disabled";
			reg = <0xfe0ba000 0x7c>;
			//clocks = <&clkc CLKID_BT656_CLK>,
			//	<&clkc CLKID_SYS_CLK_BT656_PCLK>;
			//clock-names = "cts_bt656_clk1",
			//	"clk_gate_bt656_pclk1";
			/* bt656in1, bt656in2 */
			bt656in1 {
				bt656_id = <1>;
				status = "okay";
			};
		};

		/* eARC */
		audio_earc: bus@fe333000 {
			compatible = "simple-bus";
			reg = <0xfe333000 0x1000>;
			#address-cells = <1>;
			#size-cells = <1>;
			ranges = <0x0 0xfe333000 0x1000>;
			earc: earc@0 {
				compatible = "amlogic, t5m-snd-earc";
				#sound-dai-cells = <0>;

				status = "disabled";

				reg =<0x0 0x400>,
					<0x400 0x200>,
					<0x600 0x200>;
				reg-names = "tx_cmdc",
						"tx_dmac",
						"tx_top";
				clocks = < &clkaudio CLKID_EARCTX_CMDC
						&clkaudio CLKID_EARCTX_DMAC
						&clkc CLKID_FCLK_DIV4
						&clkc CLKID_HIFI_PLL
						&clkc CLKID_HIFI_PLL
						>;
				clock-names =
						"tx_cmdc",
						"tx_dmac",
						"tx_cmdc_srcpll",
						"tx_dmac_srcpll",
						"clk_src_cd";

				interrupts = <
						GIC_SPI 49 IRQ_TYPE_LEVEL_HIGH>;
				interrupt-names ="earc_tx";
			};
		};

		//hdmirx arc
		hdmirx_arc {
			compatible = "amlogic, hdmirx-arc-iomap";
			reg = <0xfe39c000 0x3>;
			#address-cells = <1>;
			#size-cells = <1>;
			ranges = <0x0 0xfe39c000 0x3>;
			reg-names = "hdmirx-arc";
		};

		vad_open {
			compatible = "amlogic, vad-open";

			clocks = <&clkc CLKID_FCLK_DIV5
					&clkc CLKID_FCLK_DIV3
					&clkc CLKID_HIFI_PLL>;
			clock-names = "vad_srcpll", "sysclk_srcpll", "dclk_srcpll";

			interrupts = <GIC_SPI 39 IRQ_TYPE_EDGE_RISING
				GIC_SPI 44 IRQ_TYPE_EDGE_RISING>;
			interrupt-names = "irq_wakeup", "irq_frame_sync";

			pinctrl-names = "pdm_pins";
			pinctrl-0 = <&pdmin>;

			#address-cells=<1>;
			#size-cells=<1>;
			ranges;
			pdm_bus {
				reg = <0xFE332000 0x400>;
			};

			audiobus_base {
				reg = <0xFE330000 0x1000>;
			};

			vad_base {
				reg = <0xFE331800 0x400>;
			};
		};

		/* Sound iomap */
		aml_snd_iomap {
			compatible = "amlogic, snd-iomap";
			status = "okay";
			#address-cells=<1>;
			#size-cells=<1>;
			ranges;
			pdm_bus {
				reg = <0xFE331000 0x400>;
			};
			audiobus_base {
				reg = <0xFE330000 0x1000>;
			};
			audiolocker_base {
				reg = <0xFE331400 0x400>;
			};
			eqdrc_base {
				reg = <0xFE332000 0x1000>;
			};
			vad_base {
				reg = <0xFE331800 0x400>;
			};
			resampleA_base {
				reg = <0xFE331c00 0x104>;
			};
			resampleB_base {
				reg = <0xFE334000 0x104>;
			};
		};

	};
	aml_bt: aml_bt {
		compatible = "amlogic, aml-bt";
		status = "disabled";
	};

	aml_wifi: aml_wifi {
		compatible = "amlogic, aml-wifi";
		status = "disabled";
		irq_trigger_type = "GPIO_IRQ_LOW";
		//dhd_static_buf;
		pwm_config = <&wifi_pwm_conf>;
	};

	wifi_pwm_conf:wifi_pwm_conf{
		pwm_channel1_conf {
			pwms = <&pwm_ef 0 30550 0>;
			duty-cycle = <15270>;
			times = <8>;
		};
		pwm_channel2_conf {
			pwms = <&pwm_ef 2 30500 0>;
			duty-cycle = <15250>;
			times = <12>;
		};
	};

	aocec: aocec {
		compatible = "amlogic, aocec-t5m";
		dev_name = "aocec";
		status = "okay";
		vendor_name = "Amlogic"; /* Max Chars: 8     */
		/* Refer to the following URL at:
		 * http://standards.ieee.org/develop/regauth/oui/oui.txt
		 */
		vendor_id = <0x000000>;
		product_desc = "T5M"; /* Max Chars: 16    */
		cec_osd_string = "AML_TV"; /* Max Chars: 14    */
		cec_version = <5>;/*5:1.4;6:2.0*/
		port_num = <4>;
		output = <0>;
		cec_sel = <1>;/*1:use one ip, 2:use 2 ip*/
		ee_cec; /*use cec a or b*/
		arc_port_mask = <0x2>;
		interrupts = <GIC_SPI 180 IRQ_TYPE_EDGE_RISING>;/*0:snps*/
		interrupt-names = "hdmi_aocecb";
		pinctrl-names = "default","hdmitx_aocecb","cec_pin_sleep";
		pinctrl-0=<&cec_b>;
		pinctrl-1=<&cec_b>;
		pinctrl-2=<&cec_b>;
		clocks = <&clkc CLKID_CECB_32K_CLKOUT>;
		clock-names = "cecb_clk";
		reg = <0xfe044000 0x2000
		       0xfe010000 0x2000
		       0xfe000000 0x2000
		       0xfe004000 0x2000>;
		reg-names = "ao","periphs","clock","pad_reg";
		mbox-names = "mbox_cec";
		mboxes = <&mbox_fifo T5M_REE2AO_AOCEC>;
	};

	aml_dma {
		compatible = "amlogic,aml_txlx_dma";
		reg = <0xfe440400 0x48>;
		interrupts = <0 24 1>;
		status = "okay";

		aml_aes {
			compatible = "amlogic,aes_g12a_dma";
			dev_name = "aml_aes_dma";
			iv_swap = /bits/ 8 <0x0>;
			status = "okay";
		};

		aml_sha {
			compatible = "amlogic,sha_dma";
			dev_name = "aml_sha_dma";
			status = "okay";
		};

		aml_tdes {
			compatible = "amlogic,des_dma,tdes_dma";
			dev_name = "aml_tdes_dma";
			status = "okay";
		};

		crypto {
			compatible = "amlogic,crypto_sc2";
			dev_name = "aml_crypto_dev";
			status = "okay";
			thread = /bits/ 8 <0x5>;
			interrupts = <0 29 1>;
		};
	};

	rng {
		compatible = "amlogic,meson-rng";
		status = "okay";
		#address-cells = <1>;
		#size-cells = <1>;
		reg = <0xfe440788 0x0c>;
		quality = /bits/ 16 <1000>;
		version = <2>;
	};

	vclk_serve: vclk_serve {
		compatible = "amlogic, vclk_serve";
		status = "okay";
		reg = <0xfe008000 0x400    /* ana reg */
			0xfe000000 0x4a0>; /* clk reg */
	};

	di_process {
		compatible = "amlogic, di_process";
		dev_name = "di_process";
		status = "okay";
	};

	vout_mux: vout_mux {
		compatible = "amlogic, vout_mux-t5m";
		status = "okay";
		clocks = <&clkc CLKID_FCLK_DIV5>, <&clkc CLKID_VDIN_MEAS>;
		clock-names = "fclk_div5", "vdin_meas_clk";
	};

	vout: vout {
		compatible = "amlogic, vout";
		status = "okay";
		interrupts = <GIC_SPI 197 IRQ_TYPE_EDGE_RISING>;
		interrupt-names = "vsync";
		vs_meas=<0>;
	};

	vdac: vdac {
		compatible = "amlogic, vdac-t5m";
		status = "okay";
		cdac_disable = <0>;
	};

	adc: adc {
		compatible = "amlogic, adc-t5m";
		status = "okay";
		reg = <0xfe072000 0x2000/* afe reg base */
			0xfe008000 0x2000/* hiu base */
		>;
	};

	vout2: vout2 {
		compatible = "amlogic, vout2";
		status = "disabled";
	};

	dummy_venc: dummy_venc {
		compatible = "amlogic, dummy_venc_t5m";
		status = "okay";
	};

	vrr0: vrr0 {
		compatible = "amlogic, vrr-t5m";
		status = "okay";
		index = <0>;
		line_delay = <600>;
		interrupts = <0 197 1>;
		interrupt-names = "vsync";
	};

	canvas: canvas {
		compatible = "amlogic, meson, canvas";
		status = "okay";
	};

	meson_uvm {
		compatible = "amlogic, meson_uvm";
		status = "okay";
	};

	meson_videotunnel{
		compatible = "amlogic, meson_videotunnel";
		status = "okay";
	};

	rdma {
		compatible = "amlogic, meson-t3, rdma";
		status = "okay";
		interrupts = <GIC_SPI 215 IRQ_TYPE_EDGE_RISING>;
		interrupt-names = "rdma";
		/* after sc2 */
		reset-names = "rdma";
		resets = <&reset RESET_RDMA>;
		rdma_table_page_count = <16>;
	};

	codec_io: codec_io {
		compatible = "amlogic, meson-t5m, codec-io";
		status = "okay";
		#address-cells=<1>;
		#size-cells=<1>;
		ranges;
		reg =	<0xfe002000 0x2000>,
			<0xfe320000 0x10000>,
			<0x0 0x0>,
			<0x0 0x00>,
			<0xff800000 0x40000>,
			<0xfe036000 0x2000>,
			<0x0 0x0>,
			<0xfe0a8000 0x2000>;
		reg-names = "cbus",
			    "dosbus",
			    "hiubus",
			    "aobus",
			    "vcbus",
			    "dmcbus",
			    "efusebus",
				"nocbus";
	};
	amvenc_avc{
		compatible = "amlogic, amvenc_avc";
		dev_name = "amvenc_avc";
		status = "okay";
		clocks = <&clkc CLKID_HCODEC>;
		clock-names = "cts_hcodec_aclk";
		interrupts = <0 93 1>;
		interrupt-names = "mailbox_2";
		reset-names = "hcodec_rst";
		//resets = <&reset RESET_BRG_HCODEC_PIPL0>;
	};
	jpegenc{
		compatible = "amlogic, jpegenc";
		dev_name = "jpegenc";
		status = "okay";
		clocks = <&clkc CLKID_HCODEC>;
		clock-names = "clk_jpeg_enc";
		interrupts = <0 93 1>;
		interrupt-names = "mailbox_2";
		reset-names = "jpegenc_rst";
		//resets = <&reset RESET_BRG_HCODEC_PIPL0>;
	};

	ion_dev {
		status = "okay";
		compatible = "amlogic, ion_dev";
		memory-region = <&ion_cma_reserved
				&ion_fb_reserved
				&ion_secure_reserved>;
	};

	fb: fb {
		compatible = "amlogic, fb-t5m";
		memory-region = <&logo_reserved>;
		status = "disabled";
		interrupts = <GIC_SPI 197 IRQ_TYPE_EDGE_RISING
			GIC_SPI 194 IRQ_TYPE_EDGE_RISING
			GIC_SPI 215 IRQ_TYPE_EDGE_RISING>;
		interrupt-names = "viu-vsync", "viu2-vsync", "rdma";
		/* uboot logo,fb0/fb1 memory size,if afbcd fb0=0x01851000*/
		display_mode_default = "1080p60hz";
		scale_mode = <1>;
		/** 0:VPU free scale 1:OSD free scale 2:OSD super scale */
		display_size_default = <1920 1080 1920 2160 32>;
		/*1920*1080*4*3 = 0x17BB000*/
	};

	dmx_aucpu: aucpu {
		compatible = "amlogic, aucpu";
		dev_name = "aml_aucpu";
		status = "disabled";
		interrupts = <0 77 1>;
		interrupt-names = "aucpu_irq";
		#address-cells=<1>;
		#size-cells=<1>;
		ranges;
		reg = <0xfe09e080 0x100>;
	};

	ge2d {
		compatible = "amlogic, ge2d-t5m";
		status = "okay";
		interrupts = <GIC_SPI 217 IRQ_TYPE_EDGE_RISING>;
		interrupt-names = "ge2d";
		clocks = <&clkc CLKID_VAPB>,
			<&clkc CLKID_SYS_CLK_G2D>,
			<&clkc CLKID_GE2D_GATE>;
		clock-names = "clk_vapb_0",
			"clk_ge2d",
			"clk_ge2d_gate";
		reg = <0xff840000 0x100>;
		power-domains = <&pwrdm PDID_T5M_DOS_GE2D_WRAP>;
	};

	amlvecm: amlvecm {
		compatible = "amlogic, vecm-t5m";
		status = "disabled";
		dev_name = "aml_vecm";
		clocks = <&clkc CLKID_VID_LOCK>;
		clock-names = "cts_vid_lock_clk";
	};

	aml_primesl {
		compatible = "amlogic, prime_sl_t5m";
		dev_name = "amprime_sl";
		status = "okay";
	};

	amdolby_vision {
		compatible = "amlogic, dolby_vision_t5m";
		dev_name = "aml_amdolby_vision_driver";
		status = "okay";
		tv_mode = <1>;/*1:enable ;0:disable*/
	};

	mesonstream {
		compatible = "amlogic, codec, streambuf";
		dev_name = "mesonstream";
		status = "okay";
	};

	vdec {
		compatible = "amlogic, vdec-pm-pd";
		dev_name = "vdec.0";
		status = "okay";
		interrupts = <0 3 1
			0 23 1
			0 32 1
			0 91 1
			0 92 1
			0 93 1
			0 72 1>;
		interrupt-names = "vsync",
			"demux",
			"parser",
			"mailbox_0",
			"mailbox_1",
			"mailbox_2",
			"parser_b";
		power-domains = <&pwrdm PDID_T5M_DOS_HEVC>,
			<&pwrdm PDID_T5M_DOS_GE2D_WRAP>,
			<&pwrdm PDID_T5M_DOS_GE2D_WRAP>,
			<&pwrdm PDID_T5M_DOS_GE2D_WRAP>;
		power-domain-names = "pwrc-hevc",
			"pwrc-hevc-b",
			"pwrc-hcodec",
			"pwrc-vdec";
	};

	vcodec_dec {
		compatible = "amlogic, vcodec-dec";
		dev_name = "aml-vcodec-dec";
		status = "okay";
	};

	vcodec_dos_dev: vcodec_dos_dev {
		compatible = "amlogic, cpu-major-id-t5m";
		dev_name = "vcodec_dos_dev";
		status = "okay";
		reg = <0xfe320000 0x10000>,
			<0xfe036000 0x2000>;
		reg-names = "dosbus",
			"dmcbus";
		clocks = <&clkc CLKID_SYS_CLK_DOS
			&clkc CLKID_VDEC
			&clkc CLKID_HCODEC
			&clkc CLKID_HEVCB>;
		clock-names = "vdec",
			"clk_vdec_mux",
			"clk_hcodec_mux",
			"clk_hevc_mux";
		assigned-clock-parents = <&clkc CLKID_VDEC_0>,
			<&clkc CLKID_HEVCB_0>;
		assigned-clocks = <&clkc CLKID_VDEC>,
			<&clkc CLKID_HEVCB>;
	};

	meson-amvideom {
		compatible = "amlogic, amvideom-t5m";
		dev_name = "amvideom";
		status = "okay";
		interrupts = <GIC_SPI 197 IRQ_TYPE_EDGE_RISING
			GIC_SPI 194 IRQ_TYPE_EDGE_RISING
			GIC_SPI 193 IRQ_TYPE_EDGE_RISING>;
		interrupt-names = "vsync", "vsync_viu2", "pre_vsync";
	};

	vpu_security {
		compatible = "amlogic, meson-t3, vpu_security";
		status = "okay";
		interrupts = <GIC_SPI 220 IRQ_TYPE_EDGE_RISING>;
		interrupt-names = "vpu_security";
	};

	di_local {
		compatible = "amlogic, di-local";
		status = "disabled";
	};

	multi-di {
		compatible = "amlogic, dim-t3";
		status = "disabled";
		/* 0:use reserved; 1:use cma; 2:use cma as reserved */
		flag_cma = <4>;	//<1>;
		//memory-region = <&di_reserved>;
		memory-region = <&di_cma_reserved>;
		interrupts = <0 203 1
				0 202 1
				0 186 1>;
		interrupt-names = "pre_irq", "post_irq","dct_irq";
		clocks = <&clkc CLKID_VPU_CLKB>,
			<&clkc CLKID_VPU>;
		clock-names = "vpu_clkb",
			"vpu_mux";
		clock-range = <334 667>;
		/* buffer-size = <3621952>;(yuv422 8bit) */
		buffer-size = <4074560>;/*yuv422 fullpack*/
		/* reserve-iomap = "true"; */
		/* if enable nr10bit, set nr10bit-support to 1 */
		post-wr-support = <1>;
		nr10bit-support = <1>;
		nrds-enable = <1>;
		pps-enable = <1>;
		en_4k = <1>;
		keep_dec_vf = <2>;
		po_fmt = <6>;
		post_nub = <11>;
		alloc_sct = <1>;
		hf = <0>;
		dct = <2>;
		sub_v = <2>;//sub version for t5m
		afbce_loss_en = <0>;//t5w loss mode enable for DI output
		prelink_en = <1>;
		ponly_mode = <1>;
		/***************************************************
		 * t5w t3 support 4k ,same with t7 ,no canvas,
		 * post_nub---default is 11
		 *            (T7/T3/SC2/S4 new path)
		 *            post 11*5222400 = 56M,local 7*4075520 = 28m
		 * flag_cma---0: use reserved; 1:use cma;
		 *            2:use cma as reserved 4:use codec mem
		 * en_4k :en_4k---0: not support 4K;  1: enable 4K
		 *                2: dynamic: vdin: 4k enable,
		 *                   other source 4k disable
		 *                8: when 4k,
		 *                   output with a resolution is below 1080p
		 * keep_dec_vf---0:not keep; 1: keep dec vf for p;
		 *               2: dynamic keep dec vf for p,other is disable
		 * po_fmt---1: NV21/8;  2: nv12/8;  3: AFBC 422/10BIT;
		 *          4: dynamic(4K AFBC,10/422);
		 *          6: dynamic(from decoder 4K source,
		 *             out is AFBC,10/420),
		 *             other is 422/10BIT
		 * bypass_mem---0:nr not bypass; 1: nr bypass;
		 *              2: when 4k input ,nr is bypass;
		 *              3: bypass nr for 4k,but not from vdin;
		 * alloc_sct---0:not support; bit 0: for 4k; bit 1: for 1080p
		 * hf---0:not enable; 1: enable
		 * dct---0:not enable; 1: enable 1 ch; 2: enable 2 ch
		 * sub_v---0:major; 1: sub
		 * afbce_loss_en---1:check the loss flag in vf and set for di,0:disable
		 ***************************************************/
	};

	cpu_tsensor: cpu_tsensor@fe022000 {
		compatible = "amlogic, r1p1-tsensor";
		status = "okay";
		reg = <0xfe022000 0x50>;
		tsensor_id = <1>;
		cal_type = <0x11>;
		cal_coeff = <324 424 3159 9411>;
		rtemp = <120000>;
		interrupts = <GIC_SPI 83 IRQ_TYPE_LEVEL_HIGH>;
		clocks = <&clkc CLKID_TS_CLK>;
		clock-names = "ts_comp";
		#thermal-sensor-cells = <1>;
		reset-names = "ts_rst";
		resets = <&reset RESET_TS_CPU>;
		cust_governor = "power_allocator";
	};

	top_tsensor: top_tsensor@fe01c000 {
		compatible = "amlogic, r1p1-tsensor";
		status = "okay";
		reg = <0xfe01c000 0x50>;
		tsensor_id = <2>;
		cal_type = <0x11>;
		cal_coeff = <324 424 3159 9411>;
		rtemp = <120000>;
		interrupts = <GIC_SPI 85 IRQ_TYPE_LEVEL_HIGH>;
		clocks = <&clkc CLKID_TS_CLK>;
		clock-names = "ts_comp";
		#thermal-sensor-cells = <1>;
		reset-names = "ts_rst";
		resets = <&reset RESET_TS_VPU>;
	};

	meson_cooldev: meson-cooldev@0 {
		status = "okay";
		compatible = "amlogic, meson-cooldev";
		cooling_devices {
			gpufreq_cool {
				dyn_coeff = <358>;
				node_name = "valhall";
				device_type = "gpufreq";
			};
		};

	};/*meson cooling devices end*/

	thermal_zones: thermal-zones {
		soc_thermal: soc_thermal {
			polling-delay = <1000>;
			polling-delay-passive = <100>;
			sustainable-power = <2790>;
			thermal-sensors = <&cpu_tsensor 0>;
			trips {
				cpu_switch_on: trip-point@0 {
					temperature = <95000>;
					hysteresis = <5000>;
					type = "passive";
				};
				cpu_control: trip-point@1 {
					temperature = <105000>;
					hysteresis = <5000>;
					type = "passive";
				};
				cpu_critical: trip-point@2 {
					temperature = <115000>;
					hysteresis = <1000>;
					type = "critical";
				};
			};
			cooling-maps {
				cooling_map {
					trip = <&cpu_control>;
					cooling-device = <&CPU0 0 8>,
							 <&gpu 0 3>;
					contribution = <1024>;
				};
			};
		};
		top_thermal: top_thermal {
			polling-delay = <2000>;
			polling-delay-passive = <1000>;
			sustainable-power = <960>;
			thermal-sensors = <&top_tsensor 1>;
			trips {
				top_switch_on: trip-point@0 {
					temperature = <95000>;
					hysteresis = <5000>;
					type = "passive";
				};
				top_control: trip-point@1 {
					temperature = <105000>;
					hysteresis = <5000>;
					type = "passive";
				};
				top_critical: trip-point@2 {
					temperature = <115000>;
					hysteresis = <1000>;
					type = "critical";
				};
			};
		};
	};/*thermal zone end*/

	ddr_control: ddr_control {
		compatible = "amlogic, ddr-control";
		reg = <0xfe036814 0x4>,
		      <0xfe0368a4 0x4>;
		reg-names = "type-addr",
			    "freq-addr";
		type-mask = <8 8>;
		freq-mask = <0 16>;
		version = "v1";
		status = "okay";

		ddr3 {
			particle = <DDR3_PARTICLE>;
			particle-flag = <DDR_TYPE_FLAG>;
			condition-type = <DDR_THERMAL>;
			zone-name = "soc_thermal";
			refresh-constant-value;
			caddr = <0xfe0344b4>,
				<0xfe034648>,
				<0xfe0364b4>,
				<0xfe036648>;
			caddr-mask = <0 16 0 32>,
				     <0 16 0 32>;
			cstep-val = <70000 75000 80000 85000 90000>,
				    <95000 100000 105000 110000 115000 120000>;
			caddr-val = <12022 0x106c3033 12022 0x106c3033>,
				    <9616 0x106c3033 9616 0x106c3033>,
				    <7512 0x106c3033 7512 0x106c3033>,
				    <7512 0x106c3033 7512 0x106c3033>,
				    <6010 0x106c3033 6010 0x106c3033>,
				    <4808 0x106c3033 4808 0x106c3033>,
				    <4808 0x106c3033 4808 0x106c3033>,
				    <3756 0x106c3033 3756 0x106c3033>,
				    <3756 0x106c3033 3756 0x106c3033>,
				    <3004 0x106c3033 3004 0x106c3033>,
				    <1502 0x106c3033 1502 0x106c3033>;
		};

		ddr4 {
			particle = <DDR4_PARTICLE>;
			particle-flag = <DDR_TYPE_FLAG>;
			condition-type = <DDR_THERMAL>;
			zone-name = "soc_thermal";
			refresh-constant-value;
			caddr = <0xfe0344b4>,
				<0xfe034648>,
				<0xfe0364b4>,
				<0xfe036648>;
			caddr-mask = <0 16 0 32>,
				     <0 16 0 32>;
			cstep-val = <70000 75000 80000 85000 90000>,
				    <95000 100000 105000 110000 115000 120000>;
			caddr-val = <12022 0x106c3033 12022 0x106c3033>,
				    <9616 0x106c3033 9616 0x106c3033>,
				    <7512 0x106c3033 7512 0x106c3033>,
				    <7512 0x106c3033 7512 0x106c3033>,
				    <6010 0x106c3033 6010 0x106c3033>,
				    <4808 0x106c3033 4808 0x106c3033>,
				    <4808 0x106c3033 4808 0x106c3033>,
				    <3756 0x106c3033 3756 0x106c3033>,
				    <3756 0x106c3033 3756 0x106c3033>,
				    <3004 0x106c3033 3004 0x106c3033>,
				    <1502 0x106c3033 1502 0x106c3033>;
		};
	};

	usbphy0: usbphy0@fe02a000 {
		compatible = "amlogic,uphy-m31-t5m";
		#address-cells = <1>;
		#size-cells = <1>;
		//ranges = <0 0 0 0x1000>;
		status = "disabled";
		u2p0port0: u2p@0 {
			#phy-cells = <0>;
			port-speed = <0x0>; /* 0~2: HS HSP SS */
			reg = <0xfe03a08c 0x80 /* comb regs. */
					0xfe02a000 0x1000>; /* m31 regs */
			phy-otg;
			interrupts = <0 135 IRQ_TYPE_EDGE_RISING>;
		};

		u3p0port0: u3p@0 {
			#phy-cells = <0>;
			port-speed = <0x2>; /* 0~2: HS HSP SS */
			reg = <0xfe002000 0x100>;
			reset-level = <0x40>;
			phy-reg = <0xfe02a000>;
			phy-reg-size = <0x2000>;
			pipe-clk-reg = <0xfe00022c>;
			pipe-clk-reg-size = <0x4>;
			pipe-clk-gate-reg = <0xfe03a09c>;
			pipe-clk-gate-reg-size = <0x4>;
			m31phy-reset-level-bit = <45>;
			m31ctl-reset-level-bit = <6>; /* u3drd_reset */
			m31-utmi-reset-level-bit = <42>;
			u3-combx0-reset-bit = <3>;
			m31-settings = <0x1E30CE89>;
			uncomposite = <1>;
			version = <1>;
		};
	};

	usbphy1: usbphy1@fe03a000 {
		compatible = "amlogic,u2phy-aml-t5m";
		#address-cells = <1>;
		#size-cells = <1>;
		//ranges = <0 0 0 0x1000>;
		status = "disabled";
		u2p1port0: u2p@0 {
			#phy-cells = <0>;
			port-speed = <0x0>; /* 0~2: HS HSP SS */
			reg = <0xfe03a000 0x20
					0xfe002000 0x100
					0x0 0x0
					0xfe03e000 0x2000>;
			reset-level = <0x40>;
			phy-reset-level-bits = <9>;
			usb-reset-bit = <5>;
			pll-settings = <0x09400414
							0x927E0000
							0xac5f69e5
							0xbe18
							0x7
							0x78000
							0xe0004
							0xe000c>;
			dis-thred-enhance = <0x2>;
			clocks = <&clkc CLKID_SYS_CLK_USB>;
			clock-names = "crg_general";
		};
	};

	usbphy2: usbphy2@fe03a020 {
		compatible = "amlogic,u2phy-aml-t5m";
		#address-cells = <1>;
		#size-cells = <1>;
		//ranges = <0 0 0 0x1000>;
		status = "disabled";
		u2p2port0: u2p@0 {
			#phy-cells = <0>;
			port-speed = <0x0>; /* 0~2: HS HSP SS */
			reg = <0xfe03a020 0x60
					0xfe002000 0x100
					0x0 0x0
					0xfe032000 0x2000>;
			reset-level = <0x40>;
			phy-reset-level-bits = <8>;
			usb-reset-bit = <4>;
			pll-settings = <0x09400414
							0x927E0000
							0xac5f69e5
							0xbe18
							0x7
							0x78000
							0xe0004
							0xe000c>;
			dis-thred-enhance = <0x2>;
			clocks = <&clkc CLKID_SYS_CLK_USB>;
			clock-names = "crg_general";
		};
	};

	crg20: crg20@fe300000 {
		status = "disabled";
		compatible = "amlogic, crg-host-drd";
		reg = <0xfe300000 0x10000>;
		interrupts = <0 131 IRQ_TYPE_EDGE_RISING>;
		phys = <&u2p1port0>;
		phy-names = "usb2-phy";
		clocks = <&clkc CLKID_SYS_CLK_USB>;
		clock-names = "crg_general";
	};

	crg21: crg21@fe310000 {
		status = "disabled";
		compatible = "amlogic, crg-host-drd";
		reg = <0xfe310000 0x10000>;
		interrupts = <0 130 IRQ_TYPE_EDGE_RISING>;
		phys = <&u2p2port0>;
		phy-names = "usb2-phy";
		clocks = <&clkc CLKID_SYS_CLK_USB>;
		clock-names = "crg_general";
	};

	crg30_drd: crg3drd@fe350000 {
		status = "disabled";
		compatible = "amlogic, crg-drd";
		reg = <0xfe350000 0x10000>;
		interrupts = <0 129 IRQ_TYPE_EDGE_RISING>;
		phys = <&u2p0port0>, <&u3p0port0>;
		phy-names = "usb2-phy", "usb3-phy";
		clocks = <&clkc CLKID_SYS_CLK_USB>;
		clock-names = "crg_general";
	};

	crg_udc_3: crgudc3@fe350000 {
		compatible = "amlogic, crg_udc";
		status = "disable";
		device_name = "crg_udc_3";
		reg = <0xfe350000 0x10000>;
		interrupts = <0 129 IRQ_TYPE_EDGE_RISING>;
		port-speed = <3>; /** 0: default, high, 1: full */
		phys = <&u2p0port0>, <&u3p0port0>;
		phy-names = "usb2-phy", "usb3-phy";
		clocks = <&clkc CLKID_SYS_CLK_USB>;
		clock-names = "usb_general";
		controller-type = <4>;
	};

	cpu_info {
		compatible = "amlogic, cpuinfo";
		cpuinfo_cmd = <0x82000044>;
	};

	lut_dma:lut_dma {
		compatible = "amlogic, meson-t7, lut_dma";
		status = "okay";
	};

	efuse: efuse{
		compatible = "amlogic, efuse";
		read_cmd = <0x82000030>;
		write_cmd = <0x82000031>;
		get_max_cmd = <0x82000033>;
		mem_in_base_cmd = <0x82000020>;
		mem_out_base_cmd = <0x82000021>;
		efuse_pattern_size = <0x600>;
		efuse_obj_cmd_status = <0x1>;
		key = <&efusekey>;
		clock-names = "efuse_clk";
		status = "okay";
	};

	efusekey:efusekey{
		keynum = <4>;
		key0 = <&key_0>;
		key1 = <&key_1>;
		key2 = <&key_2>;
		key3 = <&key_3>;
		key_0:key_0{
			keyname = "mac";
			offset = <0>;
			size = <6>;
		};
		key_1:key_1{
			keyname = "mac_bt";
			offset = <6>;
			size = <6>;
		};
		key_2:key_2{
			keyname = "mac_wifi";
			offset = <12>;
			size = <6>;
		};
		key_3:key_3{
			keyname = "usid";
			offset = <18>;
			size = <16>;
		};
	};

	state_led: state_led {
		compatible = "amlogic,state-led-aocpu";
		mboxes = <&mbox_fifo T5M_REE2AO_LED>;
		status = "disabled";
	};

	chosen {
		bootargs = "usbcore.autosuspend=-1 dm_mod.reserved_bio_based_ios=8";
	};

	gpu_opp_table: gpu_opp_table {
		compatible = "operating-points-v2";

		opp-250 {
			opp-hz = /bits/ 64 <250000000>;
			opp-microvolt = <1150>;
		};
		opp-400 {
			opp-hz = /bits/ 64 <400000000>;
			opp-microvolt = <1150>;
		};
		opp-500 {
			opp-hz = /bits/ 64 <500000000>;
			opp-microvolt = <1150>;
		};
		opp-666 {
			opp-hz = /bits/ 64 <666666666>;
			opp-microvolt = <1150>;
		};
		opp-800 {
			opp-hz = /bits/ 64 <800000000>;
			opp-microvolt = <1150>;
		};
	};

	aml_mkl {
		compatible = "amlogic,aml_mkl";
		reg = <0xfe440200 0xf0>;
		kl_type = <1>;
		kl_vid_type = <1>;
		kl_offset = <0x80 0x88 0x8c 0x90>;
		status = "okay";
	};

	aml_kt {
		compatible = "amlogic,aml_kt";
		reg = <0xfe440500 0xa0>;
		kt_offset = <0x80 0x88 0x8c 0x90 0x94 0x98 0x9c>;
		kt_cap = <0x2407 0x6bf 0 64 0 32>;
		kt_reserved = <0>;
		kt_host_key_max_len = <32>;
		status = "okay";
	};

	fixed_area_gpu {
		compatible = "amlogic, fixed_area_cma";
		status = "disabled";
		memory-region = <&fixed_area_one>;
		pool_size = <0x400000>;
	};

	codec_mm: codec_mm {
		compatible = "amlogic, codec, mm";
		memory-region = <&codec_mm_cma &codec_mm_reserved &secure_vdec_reserved>;
		dev_name = "codec_mm";
		status = "okay";
		/*
		 * scatter_alloc_mode: the mode of scatter memory allocation
		 * 0: default mode, alloc from system and cma
		 * 1: only alloc from system
		 * 2: only alloc from cma
		 */
		scatter_alloc_mode = <2>;
	};

	ionvideo {
		compatible = "amlogic, ionvideo";
		dev_name = "ionvideo";
		status = "okay";
	};

	picdec {
		compatible = "amlogic, picdec";
		memory-region = <&picdec_cma_reserved>;
		dev_name = "picdec";
		status = "okay";
	};
	ppmgr {
		compatible = "amlogic, ppmgr";
		memory-region = <&ppmgr_reserved>;
		status = "okay";
	};
	vdetect {
		compatible = "amlogic, vdetect";
		dev_name = "vdetect";
		status = "okay";
	};

	video_queue {
		compatible = "amlogic, video_queue";
		dev_name = "videoqueue";
		status = "okay";
	};
	amlvideo2_0: amlvideo2_0 {
		compatible = "amlogic, amlvideo2";
		dev_name = "amlvideo2";
		status = "okay";
		amlvideo2_id = <0>;
		cma_mode = <1>;
	};

	amlvideo2_1: amlvideo2_1 {
		compatible = "amlogic, amlvideo2";
		dev_name = "amlvideo2";
		status = "okay";
		amlvideo2_id = <1>;
		cma_mode = <1>;
	};

	tvafe_avin_detect {
		compatible = "amlogic, t5m_tvafe_avin_detect";
		status = "okay";
		device_mask = <1>;/*bit0:ch1;bit1:ch2*/
		reg = <0xfe00a000 0x400>; /* cvbs irq base */
		interrupts = <0 173 1>,
				<0 172 1>;
	};

	tvafe {
		compatible = "amlogic, tvafe-t5m";
		/*memory-region = <&tvafe_cma_reserved>;*/
		status = "okay";
		flag_cma = <1>;/*1:share with codec_mm;0:cma alone*/
		cma_size = <5>;/*MByte*/
		reg = <0xfe072000 0x2000/*tvafe reg base*/
			0xfe008000 0x2000>; /*ana reg base*/
		reserve-iomap = "true";
		tvafe_id = <0>;
		//pinctrl-names = "default";
		/*!!particular sequence, no more and no less!!!*/
		tvafe_pin_mux = <
				3 /* TVAFE_CVBS_IN2, CVBS_IN0 = 0 */
				1 /* TVAFE_CVBS_IN0, CVBS_IN1 */
				2 /* TVAFE_CVBS_IN1, CVBS_IN2 */
				4 /* TVAFE_CVBS_IN3, CVBS_IN3 */
		>;
		clocks = <&clkc CLKID_CDAC_CLK>;
		clock-names = "vdac_clk_gate";
		cutwindow_val_h = <0 0 0 0 8>; /* level 0~4 */
		cutwindow_val_v = <4 8 14 16 24>;  /* level 0~4 */
		horizontal_dir0 = <148 148 148 148 148>;
		horizontal_dir1 = <148 168 166 160 148>;
		horizontal_stp0 = <0 0 0 0 0>;
		horizontal_stp1 = <0 0 0 0 0>;
	};

	vbi {
		compatible = "amlogic, vbi";
		status = "okay";
		interrupts = <0 210 1>;
		interrupt-names = "vsync_int";
	};

	unifykey {
		compatible = "amlogic,unifykey";
		status = "okay";

		unifykey-num = <20>;
		unifykey-index-0 = <&keysn_0>;
		unifykey-index-1 = <&keysn_1>;
		unifykey-index-2 = <&keysn_2>;
		unifykey-index-3 = <&keysn_3>;
		unifykey-index-4 = <&keysn_4>;
		unifykey-index-5 = <&keysn_5>;
		unifykey-index-6 = <&keysn_6>;
		unifykey-index-7 = <&keysn_7>;
		unifykey-index-8 = <&keysn_8>;
		unifykey-index-9 = <&keysn_9>;
		unifykey-index-10= <&keysn_10>;
		unifykey-index-11 = <&keysn_11>;
		unifykey-index-12 = <&keysn_12>;
		unifykey-index-13 = <&keysn_13>;
		unifykey-index-14 = <&keysn_14>;
		unifykey-index-15 = <&keysn_15>;
		unifykey-index-16 = <&keysn_16>;
		unifykey-index-17 = <&keysn_17>;
		unifykey-index-18 = <&keysn_18>;
		unifykey-index-19 = <&keysn_19>;

		keysn_0: key_0{
			key-name = "usid";
			key-device = "normal";
			key-permit = "read","write","del";
		};
		keysn_1:key_1{
			key-name = "mac";
			key-device  = "normal";
			key-permit = "read","write","del";
		};
		keysn_2:key_2{
			key-name = "hdcp";
			key-device = "secure";
			key-type  = "sha1";
			key-permit = "read","write","del";
		};
		keysn_3:key_3{
			key-name = "secure_boot_set";
			key-device = "efuse";
			key-permit = "write";
		};
		keysn_4:key_4{
			key-name = "mac_bt";
			key-device = "normal";
			key-permit = "read","write","del";
			key-type  = "mac";
		};
		keysn_5:key_5{
			key-name = "mac_wifi";
			key-device = "normal";
			key-permit = "read","write","del";
			key-type  = "mac";
		};
		keysn_6:key_6{
			key-name = "hdcp2_tx";
			key-device = "normal";
			key-permit = "read","write","del";
		};
		keysn_7:key_7{
			key-name = "hdcp2_rx";
			key-device = "normal";
			key-permit = "read","write","del";
		};
		keysn_8:key_8{
			key-name = "widevinekeybox";
			key-device = "secure";
			key-type = "sha1";
			key-permit = "read","write","del";
		};
		keysn_9:key_9{
			key-name = "deviceid";
			key-device = "normal";
			key-permit = "read","write","del";
		};
		keysn_10:key_10{
			key-name = "hdcp22_fw_private";
			key-device = "secure";
			key-permit = "read","write","del";
		};
		keysn_11:key_11{
			key-name = "hdcp22_rx_private";
			key-device = "secure";
			key-permit = "read","write","del";
		};
		keysn_12:key_12{
			key-name = "hdcp22_rx_fw";
			key-device = "normal";
			key-permit = "read","write","del";
		};
		keysn_13:key_13{
			key-name = "hdcp14_rx";
			key-device = "normal";
			key-type  = "sha1";
			key-permit = "read","write","del";
		};
		keysn_14:key_14{
			key-name = "prpubkeybox";// PlayReady
			key-device = "secure";
			key-permit = "read","write","del";
		};
		keysn_15:key_15{
			key-name = "prprivkeybox";// PlayReady
			key-device = "secure";
			key-permit = "read","write","del";
		};
		keysn_16:key_16{
			key-name = "attestationkeybox";// attestation key
			key-device = "secure";
			key-permit = "read","write","del";
		};
		keysn_17:key_17{
			key-name = "lcd_tcon_spi";
			key-device = "normal";
			key-permit = "read","write","del";
		};
		keysn_18:key_18{
			key-name = "attestationdevidbox";// attest dev id box
			key-device = "secure";
			key-permit = "read","write","del";
		};
		keysn_19:key_19{
			key-name = "oemkey";
			key-device = "normal";
			key-permit = "read","write","del";
		};
	}; /* End unifykey */

	hdmirx: hdmirx {
		compatible = "amlogic, hdmirx_t5m";
		#address-cells=<1>;
		#size-cells=<1>;
		/*memory-region = <&hdmirx_emp_cma_reserved>;*/
		status = "okay";
		pinctrl-names = "hdmirx_pins";
		pinctrl-0 = <&hdmirx_a_mux &hdmirx_b_mux
			&hdmirx_c_mux &hdmirx_d_mux>;
		repeat = <0>;
		/*power-domains = <&pwrdm PDIP_T5M_VPU_HDMI>;*/
		interrupts = <0 57 IRQ_TYPE_LEVEL_HIGH>;
		clocks =<&clkc CLKID_HDMIRX_CFG>,
			   <&clkc CLKID_HDMIRX_ACR>,
			   <&clkc CLKID_HDMIRX_METER>,
			   <&clkc CLKID_HDMIRX_2M>,
			   <&clkc CLKID_HDMIRX_5M>,
			   <&clkc CLKID_HDMIRX_HDCP>,
			   <&xtal>,
			   <&clkc CLKID_FCLK_DIV4>,
			   <&clkc CLKID_FCLK_DIV5>;
		clock-names = "hdmirx_cfg_clk",
				"cts_hdmirx_acr_ref_clk",
				"cts_hdmirx_meter_clk",
				"cts_hdmirx_2m_clk",
				"cts_hdmirx_5m_clk",
				"cts_hdmirx_hdcp2x_eclk",
				"xtal",
				"fclk_div4",
				"fclk_div5";
		power-domains = <&pwrdm 2>;
		hdmirx_id = <0>;
		en_4k_2_2k = <0>;
		hpd_low_cec_off = <1>;
		/* eg:0x240--HDMI0:0-HDMI1:AUTO20-HDMI2-AUTO14 */
		edid_auto_sel = <0>;
		arc_port = <1>;
		preload_port_cfg = <0x10>;
		vrr_range_dynamic_update_en = <1>;
		/* bit4: enable feature, bit3~0: port number */
		disable_port = <0x0>;
		/* MAP_ADDR_MODULE_CBUS */
		/* MAP_ADDR_MODULE_HIU */
		/* MAP_ADDR_MODULE_HDMIRX_CAPB3 */
		/* MAP_ADDR_MODULE_SEC_AHB */
		/* MAP_ADDR_MODULE_SEC_AHB2 */
		/* MAP_ADDR_MODULE_APB4 */
		/* MAP_ADDR_MODULE_TOP */
		/* MAP_ADDR_MODULE_CLK_CTRL */
		/* MAP_ADDR_MODULE_ANA_CTRL */
		reg = < 0x0 0x0
			0xff63C000 0x2000
			0xffe0d000 0x2000
			0x0 0x0
			0x0 0x0
			0x0 0x0
			0xfe398000 0x18000
			0xfe000000 0x1fff
			0xfe008000 0x334>;
	};

	aml_frc {
		compatible = "amlogic, t5m_frc";
		dev_name = "aml_frc";
		status = "disabled";
		frc_en = <1>;/*1:enable ;0:disable*/
		frc_hw_pos = <0>;/*0:before postblend; 1:after postblend*/
		interrupts = <GIC_SPI 221 IRQ_TYPE_EDGE_RISING
				GIC_SPI 222 IRQ_TYPE_EDGE_RISING
				GIC_SPI 218 IRQ_TYPE_EDGE_RISING
				GIC_SPI 128 IRQ_TYPE_EDGE_RISING>;
		interrupt-names = "irq_frc_in", "irq_frc_out", "irq_axi_crash", "irq_frc_rdma";
		memory-region = <&frc_cma_reserved>;
		clocks = <&clkc CLKID_FRC>, <&clkc CLKID_ME>;
		clock-names = "clk_frc", "clk_me";
		power-domains = <&pwrdm PDID_T5M_FRC_TOP>;
		power-domain-names = "frc-top";
		reg = <0xFF850000 0x30000 /*frc reg*/
		       0xFE000000 0x300
		       0xFF800000 0x40000>; /*vpu_reg*/
		reg-names = "frc_reg","frc_clk_reg","vpu_reg";
	};
};

&periphs_pinctrl {
	emmc_pins: emmc {
		mux-0 {
			groups = "emmc_nand_d0",
				 "emmc_nand_d1",
				 "emmc_nand_d2",
				 "emmc_nand_d3",
				 "emmc_nand_d4",
				 "emmc_nand_d5",
				 "emmc_nand_d6",
				 "emmc_nand_d7",
				 "emmc_cmd";
			function = "emmc";
			bias-pull-up;
			drive-strength-microamp = <4000>;
		};

		mux-1 {
			groups = "emmc_clk";
			function = "emmc";
			bias-disable;
			drive-strength-microamp = <4000>;
		};
	};

	emmc_ds_pins: emmc-ds {
		mux {
			groups = "emmc_nand_ds";
			function = "emmc";
			bias-pull-down;
			drive-strength-microamp = <4000>;
		};
	};

	emmc_clk_gate_pins: emmc_clk_gate {
		mux {
			groups = "GPIOB_8";
			function = "gpio_periphs";
			bias-pull-down;
			drive-strength-microamp = <4000>;
		};
	};

	pdmin: pdmin {
		mux { /* GPIOH_19, GPIOH_18 */
			groups = "pdm_dclk_h19",
				"pdm_din0_h18",
				"pdm_din1_h14";
			function = "pdm";
		};
	};

	spdif_out_a_z19_pins: spdifout_a {
		mux { /* GPIOZ_19 */
			groups = "spdif_out_a_z19";
			function = "spdif_out_a";
		};
	};

	spdifout_z19_mute: spdifout_a_mute {
		mux { /* GPIOZ-19*/
			groups = "GPIOZ_19";
			function = "gpio_periphs";
			output-low;
		};
	};

	mclk_1_h_pins: mclk_1_h_pin {
		mux { /* GPIOH_14 */
			groups = "mclk_1_h";
			function = "mclk";
		};
	};

	spdifin_m29_pins: spdifin {
		mux { /* GPIOM_29 */
			groups = "spdif_in_m";
			function = "spdif_in";
		};
	};

	/* sdemmc portB */
	sd_clk_cmd_pins:sd_clk_cmd_pins {
		mux {
			groups = "sdcard_cmd_c";
			function = "sdcard";
			bias-pull-up;
			drive-strength-microamp = <4000>;
		};
		mux1 {
			groups = "sdcard_clk_c";
			function = "sdcard";
			bias-pull-up;
			drive-strength-microamp = <4000>;
		};
	};

	sd_all_pins:sd_all_pins {
		mux {
			groups = "sdcard_d0_c",
				   "sdcard_d1_c",
				   "sdcard_d2_c",
				   "sdcard_d3_c",
				   "sdcard_cmd_c";
			function = "sdcard";
			bias-pull-up;
			drive-strength-microamp = <4000>;
		};
		mux1 {
			groups = "sdcard_clk_c";
			function = "sdcard";
			bias-pull-up;
			drive-strength-microamp = <4000>;
		};
	};

	sd_clk_gate_pins: sd_clk_gate {
		mux {
			groups = "GPIOC_4";
			function = "gpio_periphs";
			bias-pull-down;
			drive-strength-microamp = <4000>;
		};
	};

	sd_all_pd_pins:sd_all_pd_pins {
		mux {
			groups = "GPIOC_0",
				   "GPIOC_1",
				   "GPIOC_2",
				   "GPIOC_3",
				   "GPIOC_4",
				   "GPIOC_5";
			function = "gpio_periphs";
			bias-pull-down;
			output-low;
		};
	};

	sd_1bit_pins:sd_1bit_pins {
		mux {
			groups = "sdcard_d0_c",
					"sdcard_cmd_c";
			function = "sdcard";
			bias-pull-up;
			drive-strength-microamp = <4000>;
		};
		mux1 {
			groups = "sdcard_clk_c";
			function = "sdcard";
			bias-pull-up;
			drive-strength-microamp = <4000>;
		};
	};

	hdmirx_a_mux:hdmirx_a_mux {
		mux {
			groups = "hdmirx_a_hpd",
				"hdmirx_a_det",
				"hdmirx_a_sda",
				"hdmirx_a_sck";
			function = "hdmirx_a";
		};
	};

	hdmirx_b_mux:hdmirx_b_mux {
		mux {
			groups = "hdmirx_b_hpd",
				"hdmirx_b_det",
				"hdmirx_b_sda",
				"hdmirx_b_sck";
			function = "hdmirx_b";
		};
	};

	hdmirx_c_mux:hdmirx_c_mux {
		mux {
			groups = "hdmirx_c_hpd",
				"hdmirx_c_det",
				"hdmirx_c_sda",
				"hdmirx_c_sck";
			function = "hdmirx_c";
		};
	};

	hdmirx_d_mux:hdmirx_d_mux {
		mux {
			groups = "hdmirx_d_hpd",
				"hdmirx_d_det",
				"hdmirx_d_sda",
				"hdmirx_d_sck";
			function = "hdmirx_d";
		};
	};

	cec_b: cec_b {
		mux {
			groups = "cec";
			function = "cec";
		};
	};

	irblaster_pins1:irblaster_pin1 {
		mux {
			groups = "remote_out_b";
			function = "remote_out";
		};
	};

	irblaster_pins2:irblaster_pin2 {
		mux {
			groups = "remote_out_d1";
			function = "remote_out";
		};
	};

	irblaster_pins3:irblaster_pin3 {
		mux {
			groups = "remote_out_d9";
			function = "remote_out";
		};
	};

	irblaster_pins4:irblaster_pin4 {
		mux {
			groups = "remote_out_p6";
			function = "remote_out";
		};
	};

	irblaster_pins5:irblaster_pin5 {
		mux {
			groups = "remote_out_p9";
			function = "remote_out";
		};
	};

	pwm_a_pins1: pwm_a_pins1 {
		mux {
			groups = "pwm_a_e";
			function = "pwm_a";
			drive-strength-microamp = <4000>;
		};
	};

	pwm_a_pins2: pwm_a_pins2 {
		mux {
			groups = "pwm_a_d";
			function = "pwm_a";
		};
	};

	pwm_b_pins1: pwm_b_pins1 {
		mux {
			groups = "pwm_b_e";
			function = "pwm_b";
			drive-strength-microamp = <4000>;
		};
	};

	pwm_b_pins2: pwm_b_pins2 {
		mux {
			groups = "pwm_b_d";
			function = "pwm_b";
		};
	};

	pwm_c_pins1: pwm_c_pins1 {
		mux {
			groups = "pwm_c_d5";
			function = "pwm_c";
		};
	};

	pwm_c_pins2: pwm_c_pins2 {
		mux {
			groups = "pwm_c_d7";
			function = "pwm_c";
		};
	};

	pwm_c_pins3: pwm_c_pins3 {
		mux {
			groups = "pwm_c_d11";
			function = "pwm_c";
		};
	};

	pwm_d_pins1: pwm_d_pins1 {
		mux {
			groups = "pwm_d_z";
			function = "pwm_d";
		};
	};

	pwm_d_pins2: pwm_d_pins2 {
		mux {
			groups = "pwm_d_m";
			function = "pwm_d";
		};
	};

	pwm_d_pins3: pwm_d_pins3 {
		mux {
			groups = "pwm_d_d6";
			function = "pwm_d";
		};
	};

	pwm_d_pins4: pwm_d_pins4 {
		mux {
			groups = "pwm_d_d9";
			function = "pwm_d";
		};
	};

	pwm_d_pins5: pwm_d_pins5 {
		mux {
			groups = "pwm_d_h5";
			function = "pwm_d";
		};
	};

	pwm_d_pins6: pwm_d_pins6 {
		mux {
			groups = "pwm_d_h12";
			function = "pwm_d";
		};
	};

	pwm_e_pins1: pwm_e_pins1 {
		mux {
			groups = "pwm_e_z";
			function = "pwm_e";
		};
	};

	pwm_e_pins2: pwm_e_pins2 {
		mux {
			groups = "pwm_e_h";
			function = "pwm_e";
		};
	};

	pwm_e_pins3: pwm_e_pins3 {
		mux {
			groups = "pwm_e_m";
			function = "pwm_e";
		};
	};

	pwm_e_pins4: pwm_e_pins4 {
		mux {
			groups = "pwm_e_d10";
			function = "pwm_e";
		};
	};

	pwm_e_pins5: pwm_e_pins5 {
		mux {
			groups = "pwm_e_p0";
			function = "pwm_e";
		};
	};

	pwm_e_pins6: pwm_e_pins6 {
		mux {
			groups = "pwm_e_p6";
			function = "pwm_e";
		};
	};

	pwm_f_pins1: pwm_f_pins1 {
		mux {
			groups = "pwm_f_c";
			function = "pwm_f";
			drive-strength-microamp = <500>;
		};
	};

	pwm_f_pins2: pwm_f_pins2 {
		mux {
			groups = "pwm_f_d";
			function = "pwm_f";
		};
	};

	pwm_f_pins3: pwm_f_pins3 {
		mux {
			groups = "pwm_f_m26";
			function = "pwm_f";
		};
	};

	pwm_f_pins4: pwm_f_pins4 {
		mux {
			groups = "pwm_f_m10";
			function = "pwm_f";
		};
	};

	pwm_g_pins1: pwm_g_pins1 {
		mux {
			groups = "pwm_g_d";
			function = "pwm_g";
		};
	};

	pwm_g_pins2: pwm_g_pins2 {
		mux {
			groups = "pwm_g_c";
			function = "pwm_g";
		};
	};

	pwm_g_pins3: pwm_g_pins3 {
		mux {
			groups = "pwm_g_z19";
			function = "pwm_g";
		};
	};

	pwm_g_pins4: pwm_g_pins4 {
		mux {
			groups = "pwm_g_z12";
			function = "pwm_g";
		};
	};

	pwm_g_pins5: pwm_g_pins5 {
		mux {
			groups = "pwm_g_p1";
			function = "pwm_g";
		};
	};

	pwm_g_pins6: pwm_g_pins6 {
		mux {
			groups = "pwm_g_p7";
			function = "pwm_g";
		};
	};

	pwm_h_pins1: pwm_h_pins1 {
		mux {
			groups = "pwm_h_d";
			function = "pwm_h";
		};
	};

	pwm_h_pins2: pwm_h_pins2 {
		mux {
			groups = "pwm_h_c";
			function = "pwm_h";
		};
	};

	pwm_h_pins3: pwm_h_pins3 {
		mux {
			groups = "pwm_h_z";
			function = "pwm_h";
		};
	};

	pwm_h_pins4: pwm_h_pins4 {
		mux {
			groups = "pwm_h_p2";
			function = "pwm_h";
		};
	};

	pwm_h_pins5: pwm_h_pins5 {
		mux {
			groups = "pwm_h_p8";
			function = "pwm_h";
		};
	};

	pwm_c_hiz_pins: pwm_c_hiz_pins {
		mux {
			groups = "pwm_c_hiz";
			function = "pwm_c_hiz";
		};
	};

	pwm_d_hiz_pins: pwm_d_hiz_pins {
		mux {
			groups = "pwm_d_hiz";
			function = "pwm_d_hiz";
		};
	};

	lcd_vbyone_a_pins: lcd_vbyone_a_pin {
		mux {
			groups = "vx1_a_lockn","vx1_a_htpdn";
			function = "vx1";
		};
	};

	lcd_vbyone_a_off_pins: lcd_vbyone_a_off_pin {
		mux {
			groups = "GPIOH_0","GPIOH_1";
			function = "gpio_periphs";
			input-enable;
		};
	};

	lcd_tcon_p2p_pins: lcd_tcon_p2p_pin {
		mux {
			groups = "tcon_1","tcon_2","tcon_3",
				"tcon_4","tcon_5","tcon_6",
				"tcon_lock";
			function = "tcon";
		};
	};

	lcd_tcon_p2p_usit_pins: lcd_tcon_p2p_usit_pin {
		mux {
			groups = "tcon_1","tcon_2","tcon_3",
				"tcon_4","tcon_5","tcon_6",
				"tcon_sfc_h0";
			function = "tcon";
		};
	};

	lcd_tcon_p2p_off_pins: lcd_tcon_p2p_off_pin {
		mux {
			groups = "GPIOH_1","GPIOH_2","GPIOH_3",
				"GPIOH_4","GPIOH_5","GPIOH_6",
				"GPIOH_0";
				function = "gpio_periphs";
			input-enable;
		};
	};

	lcd_tcon_mlvds_pins: lcd_tcon_mlvds_pin {
		mux {
			groups = "tcon_0","tcon_1","tcon_2","tcon_3",
				"tcon_4","tcon_5","tcon_6";
			function = "tcon";
		};
	};

	lcd_tcon_mlvds_off_pins: lcd_tcon_mlvds_off_pin {
		mux {
			groups = "GPIOH_0","GPIOH_1","GPIOH_2","GPIOH_3",
				"GPIOH_4","GPIOH_5","GPIOH_6";
			function = "gpio_periphs";
			input-enable;
		};
	};

	remote_pins: remote_pin {
		mux {
			groups = "remote_input";
			function = "remote_input";
			bias-disable;
		};
	};

	spdifout_z: spdifout_z {
		mux { /* GPIOZ_19 */
			groups = "spdif_out_z19";
			function = "spdif_out";
		};
	};

	spdifout_z_mute: spdifout_z_mute {
		 mux { /* GPIOZ_19 */
			groups = "GPIOZ_19";
			function = "gpio_periphs";
			output-low;
		};
	};

	mclk_1_pins: mclk_1_pin {
	     mux { /* GPIOH_14 */
			groups = "mclk_1_h";
			function = "mclk";
		};
	};

	i2c0_pins1:i2c0_pins1 {
		mux {
			groups = "i2c0_sda_z",
				"i2c0_sck_z";
			function = "i2c0";
			drive-strength-microamp = <3000>;
			bias-disable;
		};
	};

	i2c1_pins1:i2c1_pins1 {
		mux {
			groups = "i2c1_sck_d2",
				"i2c1_sda_d3";
			function = "i2c1";
			drive-strength-microamp = <3000>;
			bias-disable;
		};
	};

	i2c1_pins2:i2c1_pins2 {
		mux {
			groups = "i2c1_sck_d13",
				"i2c1_sda_d14";
			function = "i2c1";
			drive-strength-microamp = <3000>;
			bias-disable;
		};
	};

	i2c2_pins1:i2c2_pins1 {
		mux {
			groups = "i2c2_sda_e",
				"i2c2_sck_e";
			function = "i2c2";
			drive-strength-microamp = <3000>;
			bias-disable;
		};
	};

	i2c2_pins2:i2c2_pins2 {
		mux {
			groups = "i2c2_sda_h21",
				"i2c2_sck_h20";
			function = "i2c2";
			drive-strength-microamp = <3000>;
			bias-disable;
		};
	};

	i2c2_pins3:i2c2_pins3 {
		mux {
			groups = "i2c2_sda_h11",
				"i2c2_sck_h10";
			function = "i2c2";
			drive-strength-microamp = <3000>;
			bias-disable;
		};
	};

	i2c2_pins4:i2c2_pins4 {
		mux {
			groups = "i2c2_sda_h25",
				"i2c2_sck_h24";
			function = "i2c2";
			drive-strength-microamp = <3000>;
			bias-disable;
		};
	};

	i2c2_pins5:i2c2_pins5 {
		mux {
			groups = "i2c2_sda_m",
				"i2c2_sck_m";
			function = "i2c2";
			drive-strength-microamp = <3000>;
			bias-disable;
		};
	};

	i2c3_pins1:i2c3_pins1 {
		mux {
			groups = "i2c3_sda_h23",
				"i2c3_sck_h22";
			function = "i2c3";
			drive-strength-microamp = <3000>;
			bias-disable;
		};
	};

	i2c3_pins2:i2c3_pins2 {
		mux {
			groups = "i2c3_sda_m",
				"i2c3_sck_m";
			function = "i2c3";
			drive-strength-microamp = <3000>;
			bias-disable;
		};
	};

	i2c3_pins3:i2c3_pins3 {
		mux {
			groups = "i2c3_sck_d",
				"i2c3_sda_d";
			function = "i2c3";
			drive-strength-microamp = <3000>;
			bias-disable;
		};
	};

	i2c3_pins4:i2c3_pins4 {
		mux {
			groups = "i2c3_sck_h24",
				"i2c3_sda_h25";
			function = "i2c3";
			drive-strength-microamp = <3000>;
			bias-disable;
		};
	};

	i2c3_pins5:i2c3_pins5 {
		mux {
			groups = "i2c3_sck_h28",
				"i2c3_sda_h29";
			function = "i2c3";
			drive-strength-microamp = <3000>;
			bias-disable;
		};
	};

	i2c4_pins1:i2c4_pins1 {
		mux {
			groups = "i2c4_sda_h27",
				"i2c4_sck_h26";
			function = "i2c4";
			drive-strength-microamp = <3000>;
			bias-disable;
		};
	};

	i2c4_pins2:i2c4_pins2 {
		mux {
			groups = "i2c4_sda_m",
				"i2c4_sck_m";
			function = "i2c4";
			drive-strength-microamp = <3000>;
			bias-disable;
		};
	};

	i2c4_pins3:i2c4_pins3 {
		mux {
			groups = "i2c4_sck_d",
				"i2c4_sda_d";
			function = "i2c4";
			drive-strength-microamp = <3000>;
			bias-disable;
		};
	};

	i2c4_pins4:i2c4_pins4 {
		mux {
			groups = "i2c4_sck_p",
				"i2c4_sda_p";
			function = "i2c4";
			drive-strength-microamp = <3000>;
			bias-disable;
		};
	};

	i2c4_pins5:i2c4_pins5 {
		mux {
			groups = "i2c4_sck_h20",
				"i2c4_sda_h21";
			function = "i2c4";
			drive-strength-microamp = <3000>;
			bias-disable;
		};
	};

	dcon_led_pins1:dcon_led_pins1 {
		mux {
			groups = "dcon_led_d7";
			function = "dcon_led";
			drive-strength-microamp = <3000>;
			bias-disable;
		};
	};

	dcon_led_pins2:dcon_led_pins2 {
		mux {
			groups = "dcon_led_c";
			function = "dcon_led";
			drive-strength-microamp = <3000>;
			bias-disable;
		};
	};

	dcon_led_pins3:dcon_led_pins3 {
		mux {
			groups = "dcon_led_z";
			function = "dcon_led";
			drive-strength-microamp = <3000>;
			bias-disable;
		};
	};

	dcon_led_pins4:dcon_led_pins4 {
		mux {
			groups = "dcon_led_h";
			function = "dcon_led";
			drive-strength-microamp = <3000>;
			bias-disable;
		};
	};

	dcon_led_pins5:dcon_led_pins5 {
		mux {
			groups = "dcon_led_p";
			function = "dcon_led";
			drive-strength-microamp = <3000>;
			bias-disable;
		};
	};

	dcon_led_pins6:dcon_led_pins6 {
		mux {
			groups = "dcon_led_d8";
			function = "dcon_led";
			drive-strength-microamp = <3000>;
			bias-disable;
		};
	};

	dcon_led_pins7:dcon_led_pins7 {
		mux {
			groups = "dcon_led_d9";
			function = "dcon_led";
			drive-strength-microamp = <3000>;
			bias-disable;
		};
	};

	a_uart_pins1:a_uart1 {
		mux {
			groups = "uart_a_tx_c",
				"uart_a_rx_c",
				"uart_a_cts_c",
				"uart_a_rts_c";
			function = "uart_a";
		};
	};

	a_uart_pins2:a_uart2 {
		mux {
			groups = "uart_a_tx_z",
				"uart_a_rts_z";
			function = "uart_a";
		};
		mux1 {
			groups = "uart_a_rx_z",
				"uart_a_cts_z";
			function = "uart_a";
			bias-pull-up;
		};
	};

	a_uart_pins3:a_uart3 {
		mux {
			groups = "uart_a_tx_m",
				"uart_a_rx_m",
				"uart_a_cts_m",
				"uart_a_rts_m";
			function = "uart_a";
			drive-strength-microamp = <3000>;
			bias-pull-up;
		};
	};

	c_uart_pins1:c_uart1 {
		mux {
			groups = "uart_c_tx_d",
				"uart_c_rx_d";
			function = "uart_c";
			drive-strength-microamp = <3000>;
			bias-pull-up;
		};
	};

	c_uart_pins2:c_uart2 {
		mux {
			groups = "uart_c_tx_p",
				"uart_c_rx_p",
				"uart_c_cts_p",
				"uart_c_rts_p";
			function = "uart_c";
			drive-strength-microamp = <3000>;
			bias-pull-up;
		};
	};

	c_uart_pins3:c_uart3 {
		mux {
			groups = "uart_c_tx_m",
				"uart_c_rx_m",
				"uart_c_cts_m",
				"uart_c_rts_m";
			function = "uart_c";
			drive-strength-microamp = <3000>;
			bias-pull-up;
		};
	};

	c_uart_pins4:c_uart4 {
		mux {
			groups = "uart_c_tx_h2",
				"uart_c_rx_h3",
				"uart_c_cts_h4",
				"uart_c_rts_h5";
			function = "uart_c";
			drive-strength-microamp = <3000>;
			bias-pull-up;
		};
	};

	c_uart_pins5:c_uart5 {
		mux {
			groups = "uart_c_tx_h24",
				"uart_c_rx_h25";
			function = "uart_c";
			drive-strength-microamp = <3000>;
			bias-pull-up;
		};
	};

	c_uart_pins6:c_uart6 {
		mux {
			groups = "uart_c_tx_h28",
				"uart_c_rx_h29";
			function = "uart_c";
			drive-strength-microamp = <3000>;
			bias-pull-up;
		};
	};

	jtag_a_pins: jtag_a_pin {
		mux {
			groups = "jtag_a_tdi",
				 "jtag_a_tdo",
				 "jtag_a_clk",
				 "jtag_a_tms";
			function = "jtag_a";
		};
	};

	atvdemod_agc_pins: atvdemod_agc_pins {
		mux {
			groups = "atv_if_agc_z6";
			function = "atv";
		};
	};

	dtvdemod_if_agc_pins: dtvdemod_if_agc_pins {
		mux {
			groups = "dtv_if_agc_z6";
			function = "dtv";
		};
	};

	dtvdemod_rf_agc_pins: dtvdemod_rf_agc_pins {
		mux {
			groups = "dtv_rf_agc_z6";
			function = "dtv";
		};
	};

	dvb_p_ts1_pins: dvb_p_ts1_pins {
		mux {
			groups = "tsin_b_d0",
			"tsin_b_d1",
			"tsin_b_d2",
			"tsin_b_d3",
			"tsin_b_d4",
			"tsin_b_d5",
			"tsin_b_d6",
			"tsin_b_d7",
			"tsin_b_clk",
			"tsin_b_sop",
			"tsin_b_valid";
			function = "tsin_b";
		};
	};

	dvb_ci_bus_pins_all: dvb_ci_bus_pins_all {
		mux {
			groups = "cicam_a0", "cicam_a1",
			"cicam_a2_c", "cicam_a3_c", "cicam_a4_c",
			"cicam_a5_c", "cicam_a6_c", "cicam_a7_c",
			"cicam_a8_c", "cicam_a9_c", "cicam_a10_c",
			"cicam_a11_c",
			"cicam_data0", "cicam_data1", "cicam_data2",
			"cicam_data3", "cicam_data4", "cicam_data5",
			"cicam_data6", "cicam_data7",
			"cicam_cen", "cicam_oen", "cicam_wen", "cicam_iordn",
			"cicam_iowrn", "cicam_reset";
			function = "cicam";
		};
	};

	dvb_ci_bus_pins: dvb_ci_bus_pins {
		mux {
			groups = "cicam_a0", "cicam_a1",
			"cicam_data0", "cicam_data1",
			"cicam_data2", "cicam_data3",
			"cicam_data4", "cicam_data5",
			"cicam_data6", "cicam_data7",
			"cicam_cen", "cicam_oen",
			"cicam_wen", "cicam_iordn",
			"cicam_iowrn",
			"cicam_reset";
			function = "cicam";
		};
	};
	ci_ts_pins: ci_ts_pins {
		mux {
			groups = "tsout_sop",
			"tsout_valid",
			"tsout_d0",
			"tsout_d1",
			"tsout_d2",
			"tsout_d3",
			"tsout_d4",
			"tsout_d5",
			"tsout_d6",
			"tsout_d7";
			function = "tsout";
		};
	};
	ci_addr_pins: ci_addr_pins {
		mux {
			groups = "cicam_a2_z",
			"cicam_a3_z", "cicam_a4_z",
			"cicam_a5_z", "cicam_a6_z",
			"cicam_a7_z", "cicam_a8_z",
			"cicam_a9_z",
			"cicam_a10_z", "cicam_a11_z";
			function = "cicam";
		};
	};

	ci_ts_clk_pins: ci_ts_clk_pins {
		mux {
			groups =  "tsout_clk";
			function = "tsout";
			drive-strength-microamp = <4000>;
		};
	};
	ci_gpio_pins: ci_gpio_pins {
		mux {
			groups =  "GPIOZ_7";
			function = "gpio_periphs";
		};
	};
	diseqc_out: diseqc_out {
		mux {/*only use out, don't support */
			groups = "diseqc_out_z0";
			function = "diseqc_out";
			bias-pull-down;
		};
	};

	spicc0_pins_h: spicc0_pins_h {
		mux {
			groups = "spi0_mosi_h10",
				 "spi0_miso_h9",
				 //"spi_ss0_h8",used as GPIOH_8
				 "spi0_clk_h11";
			function = "spi0";
			drive-strength-microamp = <3000>;
		};
	};

	spicc0_cs_pins: spicc0_cs_pins {
		mux {
			groups = "spi0_ss0_h8";
			function = "spi0";
			drive-strength-microamp = <3000>;
		};
	};

	spicc0_gpio_periphs_pins_h: spicc0_gpio_periphs_pins_h {
		mux {
				groups = "GPIOH_8",
					"GPIOH_9",
					"GPIOH_10",
					"GPIOH_11";
				function = "gpio_periphs";
				bias-disable;
				low-power-enable;
				drive-strength-microamp = <500>;
		};
	};

	spicc0_pins_m: spicc0_pins_m {
		mux {
			groups = "spi0_mosi_m",
				 "spi0_miso_m",
				 //"spi0_ss0_m",used as GPIOM_22
				 "spi0_clk_m";
			function = "spi0";
			drive-strength-microamp = <3000>;
		};
	};

	spicc0_gpio_periphs_pins_m: spicc0_gpio_periphs_pins_m {
		mux {
				groups = "GPIOM_19",
					"GPIOM20",
					"GPIOM_21",
					"GPIOM_22";
				function = "gpio_periphs";
				bias-disable;
				low-power-enable;
				drive-strength-microamp = <500>;
		};
	};

	spicc0_pins_z: spicc0_pins_z {
		mux {
			groups = "spi0_mosi_z",
				 "spi0_miso_z",
				 //"spi_ss0_z3",used as GPIOZ_3
				 "spi0_clk_z";
			function = "spi0";
			drive-strength-microamp = <3000>;
		};
	};

	spicc0_gpio_periphs_pins_z: spicc0_gpio_periphs_pins_z {
		mux {
				groups = "GPIOZ_0",
					"GPIOZ_1",
					"GPIOZ_2",
					"GPIOZ_3";
				function = "gpio_periphs";
				bias-disable;
				low-power-enable;
				drive-strength-microamp = <500>;
		};
	};

	spicc1_pins_h: spicc1_pins_h {
		mux {
			groups = "spi1_mosi_h",
				 "spi1_miso_h",
				 //"spi1_ss0_h",used as GPIOH_22
				 "spi1_clk_h";
			function = "spi1";
			drive-strength-microamp = <3000>;
			bias-pull-up;
		};
	};

	spicc1_cs_pins: spicc1_cs_pins {
		mux {
			groups = "spi1_ss0_h";
			function = "spi1";
			drive-strength-microamp = <3000>;
			bias-pull-up;
		};
	};

	spicc1_gpio_periphs_pins_h: spicc1_gpio_periphs_pins_h {
		mux {
				groups = "GPIOH_22",
					"GPIOH_23",
					"GPIOH_24",
					"GPIOH_25";
				function = "gpio_periphs";
				bias-disable;
				low-power-enable;
				drive-strength-microamp = <500>;
		};
	};

	spicc2_pins_c: spicc2_pins_c {
		mux {
			groups = "spi2_mosi_c",
				 "spi2_miso_c",
				 //"spi2_ss0_c",used as GPIOC_3
				 "spi2_clk_c";
			function = "spi2";
			drive-strength-microamp = <3000>;
		};
	};

	spicc2_cs_pins: spicc2_cs_pins {
		mux {
			groups = "spi2_ss0_c";
			function = "spi1";
			drive-strength-microamp = <3000>;
			bias-pull-up;
		};
	};

	spicc2_gpio_periphs_pins_c: spicc2_gpio_periphs_pins_c {
		mux {
				groups = "GPIOC_0",
					"GPIOC_1",
					"GPIOC_2",
					"GPIOC_3";
				function = "gpio_periphs";
				bias-disable;
				low-power-enable;
				drive-strength-microamp = <500>;
		};
	};

	spicc2_pins_m: spicc2_pins_m {
		mux {
			groups = "spi2_mosi_m",
					"spi2_miso_m",
					//"spi2_ss0_m",used as GPIOM_3
					"spi2_clk_m";
			function = "spi2";
			drive-strength-microamp = <3000>;
		};
	};

	spicc2_gpio_periphs_pins_m: spicc2_gpio_periphs_pins_m {
		mux {
				groups = "GPIOM_0",
					"GPIOM_1",
					"GPIOM_2",
					"GPIOM_3";
				function = "gpio_periphs";
				bias-disable;
				low-power-enable;
				drive-strength-microamp = <500>;
		};
	};

	spicc2_pins_p: spicc2_pins_p {
		mux {
			groups = "spi2_mosi_p",
						"spi2_miso_p",
						//"spi2_ss0_p",used as GPIOP_3
						"spi2_clk_p";
			function = "spi2";
			drive-strength-microamp = <3000>;
		};
	};

	spicc2_gpio_periphs_pins_p: spicc2_gpio_periphs_pins_p {
		mux {
				groups = "GPIOP_0",
					"GPIOP_1",
					"GPIOP_2",
					"GPIOP_3";
				function = "gpio_periphs";
				bias-disable;
				low-power-enable;
				drive-strength-microamp = <500>;
		};
	};

	spifc_all_pins: spifc_all_pins {
		mux {
			groups = "spif_hold",
				"spif_mo",
				"spif_mi",
				"spif_clk",
				"spif_wp",
				"spif_cs";
			function = "spif";
			drive-strength-microamp = <3000>;
		};
	};

	sd_iso7816_pins:sd_iso7816_pins {
		mux {
			groups = "iso7816_clk_z",
				"iso7816_data_z";
			function = "iso7816";
			input-enable;
			bias-pull-down;
		};
	};
};

&gpu{
	status = "okay";
	operating-points-v2 = <&gpu_opp_table>;
	reg =   <0xFE400000 0x04000>, /*mali APB bus base address*/
		<0xFE002000 0x01000>, /*reset register*/
		<0xFE000000 0x01000>; /*hiu register*/

	interrupts = <GIC_SPI 144 IRQ_TYPE_LEVEL_HIGH>,
		     <GIC_SPI 145 IRQ_TYPE_LEVEL_HIGH>,
		     <GIC_SPI 146 IRQ_TYPE_LEVEL_HIGH>;
	interrupt-names = "GPU", "MMU", "JOB";
	num_of_pp = <2>;
	system-coherency = <31>;
	clocks = <&clkc CLKID_MALI>;
	clock-names = "gpu_mux";

	/*
	 * Mali clocking is provided by two identical clock paths
	 * MALI_0 and MALI_1 muxed to a single clock by a glitch
	 * free mux to safely change frequency while running.
	 */
	assigned-clocks = <&clkc CLKID_MALI_0_SEL>,
			  <&clkc CLKID_MALI_0>,
			  <&clkc CLKID_MALI>; /* Glitch free mux */
	assigned-clock-parents = <&clkc CLKID_FCLK_DIV2P5>,
				 <0>, /* Do Nothing */
				 <&clkc CLKID_MALI_0>;
	assigned-clock-rates = <0>, /* Do Nothing */
			       <800000000>,
			       <0>; /* Do Nothing */

	tbl =  <&dvfs250_cfg
		&dvfs400_cfg
		&dvfs500_cfg
		&dvfs666_cfg
		&dvfs800_cfg
		&dvfs800_cfg>;

};

#include "meson-t5m-cpufreq.dtsi"
